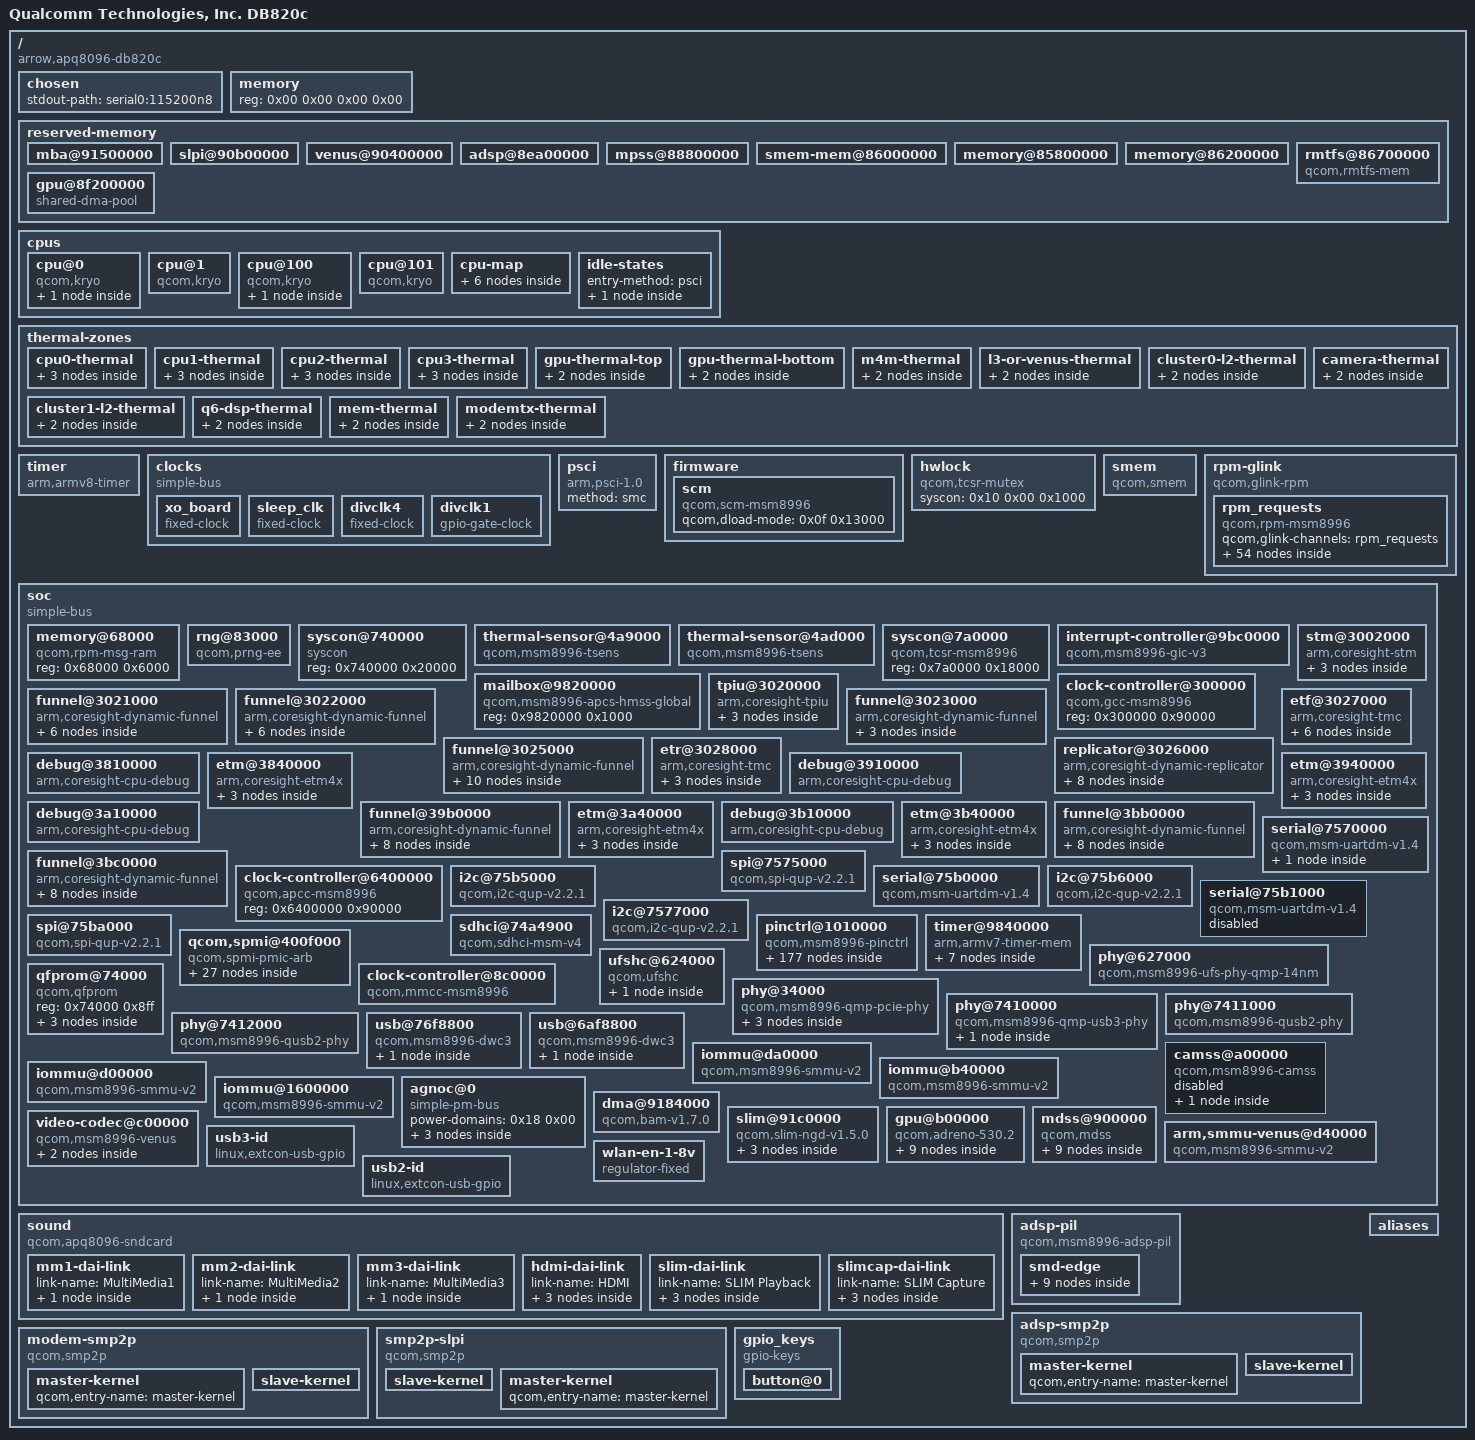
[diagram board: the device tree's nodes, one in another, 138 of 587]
/dts-v1/;

/ {
	interrupt-parent = <0x01>;
	#address-cells = <0x02>;
	#size-cells = <0x02>;
	model = "Qualcomm Technologies, Inc. DB820c";
	compatible = "arrow,apq8096-db820c\0qcom,apq8096-sbc\0qcom,apq8096";

	chosen {
		stdout-path = "serial0:115200n8";
	};

	memory {
		device_type = "memory";
		reg = <0x00 0x00 0x00 0x00>;
	};

	reserved-memory {
		#address-cells = <0x02>;
		#size-cells = <0x02>;
		ranges;

		mba@91500000 {
			reg = <0x00 0x91500000 0x00 0x200000>;
			no-map;
			phandle = <0x9d>;
		};

		slpi@90b00000 {
			reg = <0x00 0x90b00000 0x00 0xa00000>;
			no-map;
			phandle = <0x9e>;
		};

		venus@90400000 {
			reg = <0x00 0x90400000 0x00 0x700000>;
			no-map;
			phandle = <0x8f>;
		};

		adsp@8ea00000 {
			reg = <0x00 0x8ea00000 0x00 0x1a00000>;
			no-map;
			phandle = <0x99>;
		};

		mpss@88800000 {
			reg = <0x00 0x88800000 0x00 0x6200000>;
			no-map;
			phandle = <0x9f>;
		};

		smem-mem@86000000 {
			reg = <0x00 0x86000000 0x00 0x200000>;
			no-map;
			phandle = <0x11>;
		};

		memory@85800000 {
			reg = <0x00 0x85800000 0x00 0x800000>;
			no-map;
		};

		memory@86200000 {
			reg = <0x00 0x86200000 0x00 0x2600000>;
			no-map;
		};

		rmtfs@86700000 {
			compatible = "qcom,rmtfs-mem";
			size = <0x00 0x200000>;
			alloc-ranges = <0x00 0xa0000000 0x00 0x2000000>;
			no-map;
			qcom,client-id = <0x01>;
			qcom,vmid = <0x0f>;
		};

		gpu@8f200000 {
			compatible = "shared-dma-pool";
			reg = <0x00 0x90b00000 0x00 0xa00000>;
			no-map;
			phandle = <0x84>;
		};
	};

	cpus {
		#address-cells = <0x02>;
		#size-cells = <0x00>;

		cpu@0 {
			device_type = "cpu";
			compatible = "qcom,kryo";
			reg = <0x00 0x00>;
			enable-method = "psci";
			cpu-idle-states = <0x02>;
			capacity-dmips-mhz = <0x400>;
			next-level-cache = <0x03>;
			phandle = <0x05>;

			l2-cache {
				compatible = "cache";
				cache-level = <0x02>;
				phandle = <0x03>;
			};
		};

		cpu@1 {
			device_type = "cpu";
			compatible = "qcom,kryo";
			reg = <0x00 0x01>;
			enable-method = "psci";
			cpu-idle-states = <0x02>;
			capacity-dmips-mhz = <0x400>;
			next-level-cache = <0x03>;
			phandle = <0x06>;
		};

		cpu@100 {
			device_type = "cpu";
			compatible = "qcom,kryo";
			reg = <0x00 0x100>;
			enable-method = "psci";
			cpu-idle-states = <0x02>;
			capacity-dmips-mhz = <0x400>;
			next-level-cache = <0x04>;
			phandle = <0x07>;

			l2-cache {
				compatible = "cache";
				cache-level = <0x02>;
				phandle = <0x04>;
			};
		};

		cpu@101 {
			device_type = "cpu";
			compatible = "qcom,kryo";
			reg = <0x00 0x101>;
			enable-method = "psci";
			cpu-idle-states = <0x02>;
			capacity-dmips-mhz = <0x400>;
			next-level-cache = <0x04>;
			phandle = <0x08>;
		};

		cpu-map {

			cluster0 {

				core0 {
					cpu = <0x05>;
				};

				core1 {
					cpu = <0x06>;
				};
			};

			cluster1 {

				core0 {
					cpu = <0x07>;
				};

				core1 {
					cpu = <0x08>;
				};
			};
		};

		idle-states {
			entry-method = "psci";

			cpu-sleep-0 {
				compatible = "arm,idle-state";
				idle-state-name = "standalone-power-collapse";
				arm,psci-suspend-param = <0x04>;
				entry-latency-us = <0x82>;
				exit-latency-us = <0x50>;
				min-residency-us = <0x12c>;
				phandle = <0x02>;
			};
		};
	};

	thermal-zones {

		cpu0-thermal {
			polling-delay-passive = <0xfa>;
			polling-delay = <0x3e8>;
			thermal-sensors = <0x09 0x03>;

			trips {

				trip-point@0 {
					temperature = <0x124f8>;
					hysteresis = <0x7d0>;
					type = "passive";
					phandle = <0xa0>;
				};

				cpu_crit {
					temperature = <0x1adb0>;
					hysteresis = <0x7d0>;
					type = "critical";
					phandle = <0xa1>;
				};
			};
		};

		cpu1-thermal {
			polling-delay-passive = <0xfa>;
			polling-delay = <0x3e8>;
			thermal-sensors = <0x09 0x05>;

			trips {

				trip-point@0 {
					temperature = <0x124f8>;
					hysteresis = <0x7d0>;
					type = "passive";
					phandle = <0xa2>;
				};

				cpu_crit {
					temperature = <0x1adb0>;
					hysteresis = <0x7d0>;
					type = "critical";
					phandle = <0xa3>;
				};
			};
		};

		cpu2-thermal {
			polling-delay-passive = <0xfa>;
			polling-delay = <0x3e8>;
			thermal-sensors = <0x09 0x08>;

			trips {

				trip-point@0 {
					temperature = <0x124f8>;
					hysteresis = <0x7d0>;
					type = "passive";
					phandle = <0xa4>;
				};

				cpu_crit {
					temperature = <0x1adb0>;
					hysteresis = <0x7d0>;
					type = "critical";
					phandle = <0xa5>;
				};
			};
		};

		cpu3-thermal {
			polling-delay-passive = <0xfa>;
			polling-delay = <0x3e8>;
			thermal-sensors = <0x09 0x0a>;

			trips {

				trip-point@0 {
					temperature = <0x124f8>;
					hysteresis = <0x7d0>;
					type = "passive";
					phandle = <0xa6>;
				};

				cpu_crit {
					temperature = <0x1adb0>;
					hysteresis = <0x7d0>;
					type = "critical";
					phandle = <0xa7>;
				};
			};
		};

		gpu-thermal-top {
			polling-delay-passive = <0xfa>;
			polling-delay = <0x3e8>;
			thermal-sensors = <0x0a 0x06>;

			trips {

				trip-point@0 {
					temperature = <0x15f90>;
					hysteresis = <0x7d0>;
					type = "hot";
					phandle = <0xa8>;
				};
			};
		};

		gpu-thermal-bottom {
			polling-delay-passive = <0xfa>;
			polling-delay = <0x3e8>;
			thermal-sensors = <0x0a 0x07>;

			trips {

				trip-point@0 {
					temperature = <0x15f90>;
					hysteresis = <0x7d0>;
					type = "hot";
					phandle = <0xa9>;
				};
			};
		};

		m4m-thermal {
			polling-delay-passive = <0xfa>;
			polling-delay = <0x3e8>;
			thermal-sensors = <0x09 0x01>;

			trips {

				trip-point@0 {
					temperature = <0x15f90>;
					hysteresis = <0x7d0>;
					type = "hot";
					phandle = <0xaa>;
				};
			};
		};

		l3-or-venus-thermal {
			polling-delay-passive = <0xfa>;
			polling-delay = <0x3e8>;
			thermal-sensors = <0x09 0x02>;

			trips {

				trip-point@0 {
					temperature = <0x15f90>;
					hysteresis = <0x7d0>;
					type = "hot";
					phandle = <0xab>;
				};
			};
		};

		cluster0-l2-thermal {
			polling-delay-passive = <0xfa>;
			polling-delay = <0x3e8>;
			thermal-sensors = <0x09 0x07>;

			trips {

				trip-point@0 {
					temperature = <0x15f90>;
					hysteresis = <0x7d0>;
					type = "hot";
					phandle = <0xac>;
				};
			};
		};

		cluster1-l2-thermal {
			polling-delay-passive = <0xfa>;
			polling-delay = <0x3e8>;
			thermal-sensors = <0x09 0x0c>;

			trips {

				trip-point@0 {
					temperature = <0x15f90>;
					hysteresis = <0x7d0>;
					type = "hot";
					phandle = <0xad>;
				};
			};
		};

		camera-thermal {
			polling-delay-passive = <0xfa>;
			polling-delay = <0x3e8>;
			thermal-sensors = <0x0a 0x01>;

			trips {

				trip-point@0 {
					temperature = <0x15f90>;
					hysteresis = <0x7d0>;
					type = "hot";
					phandle = <0xae>;
				};
			};
		};

		q6-dsp-thermal {
			polling-delay-passive = <0xfa>;
			polling-delay = <0x3e8>;
			thermal-sensors = <0x0a 0x02>;

			trips {

				trip-point@0 {
					temperature = <0x15f90>;
					hysteresis = <0x7d0>;
					type = "hot";
					phandle = <0xaf>;
				};
			};
		};

		mem-thermal {
			polling-delay-passive = <0xfa>;
			polling-delay = <0x3e8>;
			thermal-sensors = <0x0a 0x03>;

			trips {

				trip-point@0 {
					temperature = <0x15f90>;
					hysteresis = <0x7d0>;
					type = "hot";
					phandle = <0xb0>;
				};
			};
		};

		modemtx-thermal {
			polling-delay-passive = <0xfa>;
			polling-delay = <0x3e8>;
			thermal-sensors = <0x0a 0x04>;

			trips {

				trip-point@0 {
					temperature = <0x15f90>;
					hysteresis = <0x7d0>;
					type = "hot";
					phandle = <0xb1>;
				};
			};
		};
	};

	timer {
		compatible = "arm,armv8-timer";
		interrupts = <0x01 0x0d 0x08 0x01 0x0e 0x08 0x01 0x0b 0x08 0x01 0x0a 0x08>;
	};

	clocks {
		compatible = "simple-bus";

		xo_board {
			compatible = "fixed-clock";
			#clock-cells = <0x00>;
			clock-frequency = <0x124f800>;
			clock-output-names = "xo_board";
			phandle = <0x48>;
		};

		sleep_clk {
			compatible = "fixed-clock";
			#clock-cells = <0x00>;
			clock-frequency = <0x7ffc>;
			clock-output-names = "sleep_clk";
			phandle = <0xb2>;
		};

		divclk4 {
			compatible = "fixed-clock";
			#clock-cells = <0x00>;
			clock-frequency = <0x8000>;
			clock-output-names = "divclk4";
			pinctrl-names = "default";
			pinctrl-0 = <0x0b>;
			phandle = <0x39>;
		};

		divclk1 {
			compatible = "gpio-gate-clock";
			pinctrl-0 = <0x0c>;
			pinctrl-names = "default";
			clocks = <0x0d 0x2e>;
			#clock-cells = <0x00>;
			enable-gpios = <0x0e 0x0f 0x00>;
			phandle = <0x80>;
		};
	};

	psci {
		compatible = "arm,psci-1.0";
		method = "smc";
	};

	firmware {

		scm {
			compatible = "qcom,scm-msm8996";
			qcom,dload-mode = <0x0f 0x13000>;
		};
	};

	hwlock {
		compatible = "qcom,tcsr-mutex";
		syscon = <0x10 0x00 0x1000>;
		#hwlock-cells = <0x01>;
		phandle = <0x12>;
	};

	smem {
		compatible = "qcom,smem";
		memory-region = <0x11>;
		hwlocks = <0x12 0x03>;
	};

	rpm-glink {
		compatible = "qcom,glink-rpm";
		interrupts = <0x00 0xa8 0x01>;
		qcom,rpm-msg-ram = <0x13>;
		mboxes = <0x14 0x00>;

		rpm_requests {
			compatible = "qcom,rpm-msm8996";
			qcom,glink-channels = "rpm_requests";

			qcom,rpmcc {
				compatible = "qcom,rpmcc-msm8996";
				#clock-cells = <0x01>;
				phandle = <0x0d>;
			};

			power-controller {
				compatible = "qcom,msm8996-rpmpd";
				#power-domain-cells = <0x01>;
				operating-points-v2 = <0x15>;
				phandle = <0xb3>;

				opp-table {
					compatible = "operating-points-v2";
					phandle = <0x15>;

					opp1 {
						opp-level = <0x01>;
						phandle = <0xb4>;
					};

					opp2 {
						opp-level = <0x02>;
						phandle = <0xb5>;
					};

					opp3 {
						opp-level = <0x03>;
						phandle = <0xb6>;
					};

					opp4 {
						opp-level = <0x04>;
						phandle = <0xb7>;
					};

					opp5 {
						opp-level = <0x05>;
						phandle = <0xb8>;
					};

					opp6 {
						opp-level = <0x06>;
						phandle = <0xb9>;
					};
				};
			};

			pm8994-regulators {
				compatible = "qcom,rpm-pm8994-regulators";
				vdd_l1-supply = <0x16>;
				vdd_l2_l26_l28-supply = <0x16>;
				vdd_l3_l11-supply = <0x16>;
				vdd_l4_l27_l31-supply = <0x16>;
				vdd_l5_l7-supply = <0x17>;
				vdd_l14_l15-supply = <0x17>;
				vdd_l20_l21-supply = <0x17>;
				vdd_l25-supply = <0x16>;

				s1 {
					phandle = <0xba>;
				};

				s2 {
					phandle = <0xbb>;
				};

				s3 {
					regulator-min-microvolt = <0x13d620>;
					regulator-max-microvolt = <0x13d620>;
					phandle = <0x16>;
				};

				s4 {
					regulator-min-microvolt = <0x1b7740>;
					regulator-max-microvolt = <0x1b7740>;
					regulator-always-on;
					phandle = <0x5d>;
				};

				s5 {
					regulator-min-microvolt = <0x20ce70>;
					regulator-max-microvolt = <0x20ce70>;
					phandle = <0x17>;
				};

				s6 {
					phandle = <0xbc>;
				};

				s7 {
					regulator-min-microvolt = <0xc3500>;
					regulator-max-microvolt = <0xc3500>;
					phandle = <0xbd>;
				};

				s8 {
					phandle = <0xbe>;
				};

				s9 {
					phandle = <0xbf>;
				};

				s10 {
					phandle = <0xc0>;
				};

				s11 {
					phandle = <0xc1>;
				};

				s12 {
					phandle = <0xc2>;
				};

				l1 {
					regulator-min-microvolt = <0xf4240>;
					regulator-max-microvolt = <0xf4240>;
					phandle = <0xc3>;
				};

				l2 {
					regulator-min-microvolt = <0x1312d0>;
					regulator-max-microvolt = <0x1312d0>;
					phandle = <0x67>;
				};

				l3 {
					regulator-min-microvolt = <0xcf850>;
					regulator-max-microvolt = <0xcf850>;
					phandle = <0xc4>;
				};

				l4 {
					regulator-min-microvolt = <0x12b128>;
					regulator-max-microvolt = <0x12b128>;
					phandle = <0xc5>;
				};

				l5 {
					phandle = <0xc6>;
				};

				l6 {
					regulator-min-microvolt = <0x124f80>;
					regulator-max-microvolt = <0x124f80>;
					phandle = <0xc7>;
				};

				l7 {
					phandle = <0xc8>;
				};

				l8 {
					regulator-min-microvolt = <0x1b7740>;
					regulator-max-microvolt = <0x1b7740>;
					phandle = <0xc9>;
				};

				l9 {
					regulator-min-microvolt = <0x1b7740>;
					regulator-max-microvolt = <0x1b7740>;
					phandle = <0xca>;
				};

				l10 {
					regulator-min-microvolt = <0x1b7740>;
					regulator-max-microvolt = <0x1b7740>;
					phandle = <0xcb>;
				};

				l11 {
					regulator-min-microvolt = <0x118c30>;
					regulator-max-microvolt = <0x118c30>;
					phandle = <0xcc>;
				};

				l12 {
					regulator-min-microvolt = <0x1b7740>;
					regulator-max-microvolt = <0x1b7740>;
					phandle = <0x58>;
				};

				l13 {
					regulator-min-microvolt = <0x1b7740>;
					regulator-max-microvolt = <0x2d0370>;
					phandle = <0x53>;
				};

				l14 {
					regulator-min-microvolt = <0x1b7740>;
					regulator-max-microvolt = <0x1b7740>;
					phandle = <0xcd>;
				};

				l15 {
					regulator-min-microvolt = <0x1b7740>;
					regulator-max-microvolt = <0x1b7740>;
					phandle = <0xce>;
				};

				l16 {
					regulator-min-microvolt = <0x2932e0>;
					regulator-max-microvolt = <0x2932e0>;
					phandle = <0xcf>;
				};

				l17 {
					regulator-min-microvolt = <0x2625a0>;
					regulator-max-microvolt = <0x2625a0>;
					phandle = <0xd0>;
				};

				l18 {
					regulator-min-microvolt = <0x2932e0>;
					regulator-max-microvolt = <0x2c4020>;
					phandle = <0xd1>;
				};

				l19 {
					regulator-min-microvolt = <0x2dc6c0>;
					regulator-max-microvolt = <0x2dc6c0>;
					phandle = <0xd2>;
				};

				l20 {
					regulator-min-microvolt = <0x2d0370>;
					regulator-max-microvolt = <0x2d0370>;
					regulator-allow-set-load;
					phandle = <0x5c>;
				};

				l21 {
					regulator-min-microvolt = <0x2d0370>;
					regulator-max-microvolt = <0x2d0370>;
					regulator-allow-set-load;
					regulator-system-load = <0x30d40>;
					phandle = <0x52>;
				};

				l22 {
					regulator-min-microvolt = <0x325aa0>;
					regulator-max-microvolt = <0x325aa0>;
					phandle = <0xd3>;
				};

				l23 {
					regulator-min-microvolt = <0x2ab980>;
					regulator-max-microvolt = <0x2ab980>;
					phandle = <0xd4>;
				};

				l24 {
					regulator-min-microvolt = <0x2eebb8>;
					regulator-max-microvolt = <0x2eebb8>;
					phandle = <0x5f>;
				};

				l25 {
					regulator-min-microvolt = <0x124f80>;
					regulator-max-microvolt = <0x124f80>;
					regulator-allow-set-load;
					phandle = <0x59>;
				};

				l26 {
					phandle = <0xd5>;
				};

				l27 {
					regulator-min-microvolt = <0xf4240>;
					regulator-max-microvolt = <0xf4240>;
					phandle = <0xd6>;
				};

				l28 {
					regulator-min-microvolt = <0xe1d48>;
					regulator-max-microvolt = <0xe1d48>;
					regulator-allow-set-load;
					phandle = <0x57>;
				};

				l29 {
					regulator-min-microvolt = <0x2ab980>;
					regulator-max-microvolt = <0x2ab980>;
					phandle = <0xd7>;
				};

				l30 {
					regulator-min-microvolt = <0x1b7740>;
					regulator-max-microvolt = <0x1b7740>;
					phandle = <0xd8>;
				};

				l31 {
					phandle = <0xd9>;
				};

				l32 {
					regulator-min-microvolt = <0x1b7740>;
					regulator-max-microvolt = <0x1b7740>;
					phandle = <0xda>;
				};
			};
		};
	};

	soc {
		#address-cells = <0x01>;
		#size-cells = <0x01>;
		ranges = <0x00 0x00 0x00 0xffffffff>;
		compatible = "simple-bus";
		phandle = <0xdb>;

		memory@68000 {
			compatible = "qcom,rpm-msg-ram";
			reg = <0x68000 0x6000>;
			phandle = <0x13>;
		};

		rng@83000 {
			compatible = "qcom,prng-ee";
			reg = <0x83000 0x1000>;
			clocks = <0x18 0x98>;
			clock-names = "core";
			phandle = <0xdc>;
		};

		syscon@740000 {
			compatible = "syscon";
			reg = <0x740000 0x20000>;
			phandle = <0x10>;
		};

		thermal-sensor@4a9000 {
			compatible = "qcom,msm8996-tsens";
			reg = <0x4a9000 0x1000 0x4a8000 0x1000>;
			#qcom,sensors = <0x0d>;
			#thermal-sensor-cells = <0x01>;
			phandle = <0x09>;
		};

		thermal-sensor@4ad000 {
			compatible = "qcom,msm8996-tsens";
			reg = <0x4ad000 0x1000 0x4ac000 0x1000>;
			#qcom,sensors = <0x08>;
			#thermal-sensor-cells = <0x01>;
			phandle = <0x0a>;
		};

		syscon@7a0000 {
			compatible = "qcom,tcsr-msm8996\0syscon";
			reg = <0x7a0000 0x18000>;
			phandle = <0x0f>;
		};

		interrupt-controller@9bc0000 {
			compatible = "qcom,msm8996-gic-v3\0arm,gic-v3";
			#interrupt-cells = <0x03>;
			interrupt-controller;
			#redistributor-regions = <0x01>;
			redistributor-stride = <0x00 0x40000>;
			reg = <0x9bc0000 0x10000 0x9c00000 0x100000>;
			interrupts = <0x01 0x09 0x04>;
			phandle = <0x01>;
		};

		mailbox@9820000 {
			compatible = "qcom,msm8996-apcs-hmss-global";
			reg = <0x9820000 0x1000>;
			#mbox-cells = <0x01>;
			phandle = <0x14>;
		};

		clock-controller@300000 {
			compatible = "qcom,gcc-msm8996";
			#clock-cells = <0x01>;
			#reset-cells = <0x01>;
			#power-domain-cells = <0x01>;
			reg = <0x300000 0x90000>;
			phandle = <0x18>;
		};

		stm@3002000 {
			compatible = "arm,coresight-stm\0arm,primecell";
			reg = <0x3002000 0x1000 0x8280000 0x180000>;
			reg-names = "stm-base\0stm-stimulus-base";
			clocks = <0x0d 0x08 0x0d 0x09>;
			clock-names = "apb_pclk\0atclk";

			out-ports {

				port {

					endpoint {
						remote-endpoint = <0x19>;
						phandle = <0x1b>;
					};
				};
			};
		};

		tpiu@3020000 {
			compatible = "arm,coresight-tpiu\0arm,primecell";
			reg = <0x3020000 0x1000>;
			clocks = <0x0d 0x08 0x0d 0x09>;
			clock-names = "apb_pclk\0atclk";

			in-ports {

				port {

					endpoint {
						remote-endpoint = <0x1a>;
						phandle = <0x26>;
					};
				};
			};
		};

		funnel@3021000 {
			compatible = "arm,coresight-dynamic-funnel\0arm,primecell";
			reg = <0x3021000 0x1000>;
			clocks = <0x0d 0x08 0x0d 0x09>;
			clock-names = "apb_pclk\0atclk";

			in-ports {
				#address-cells = <0x01>;
				#size-cells = <0x00>;

				port@7 {
					reg = <0x07>;

					endpoint {
						remote-endpoint = <0x1b>;
						phandle = <0x19>;
					};
				};
			};

			out-ports {

				port {

					endpoint {
						remote-endpoint = <0x1c>;
						phandle = <0x20>;
					};
				};
			};
		};

		funnel@3022000 {
			compatible = "arm,coresight-dynamic-funnel\0arm,primecell";
			reg = <0x3022000 0x1000>;
			clocks = <0x0d 0x08 0x0d 0x09>;
			clock-names = "apb_pclk\0atclk";

			in-ports {
				#address-cells = <0x01>;
				#size-cells = <0x00>;

				port@6 {
					reg = <0x06>;

					endpoint {
						remote-endpoint = <0x1d>;
						phandle = <0x36>;
					};
				};
			};

			out-ports {

				port {

					endpoint {
						remote-endpoint = <0x1e>;
						phandle = <0x21>;
					};
				};
			};
		};

		funnel@3023000 {
			compatible = "arm,coresight-dynamic-funnel\0arm,primecell";
			reg = <0x3023000 0x1000>;
			clocks = <0x0d 0x08 0x0d 0x09>;
			clock-names = "apb_pclk\0atclk";

			out-ports {

				port {

					endpoint {
						remote-endpoint = <0x1f>;
						phandle = <0x22>;
					};
				};
			};
		};

		funnel@3025000 {
			compatible = "arm,coresight-dynamic-funnel\0arm,primecell";
			reg = <0x3025000 0x1000>;
			clocks = <0x0d 0x08 0x0d 0x09>;
			clock-names = "apb_pclk\0atclk";

			in-ports {
				#address-cells = <0x01>;
				#size-cells = <0x00>;

				port@0 {
					reg = <0x00>;

					endpoint {
						remote-endpoint = <0x20>;
						phandle = <0x1c>;
					};
				};

				port@1 {
					reg = <0x01>;

					endpoint {
						remote-endpoint = <0x21>;
						phandle = <0x1e>;
					};
				};

				port@2 {
					reg = <0x02>;

					endpoint {
						remote-endpoint = <0x22>;
						phandle = <0x1f>;
					};
				};
			};

			out-ports {

				port {

					endpoint {
						remote-endpoint = <0x23>;
						phandle = <0x27>;
					};
				};
			};
		};

		replicator@3026000 {
			compatible = "arm,coresight-dynamic-replicator\0arm,primecell";
			reg = <0x3026000 0x1000>;
			clocks = <0x0d 0x08 0x0d 0x09>;
			clock-names = "apb_pclk\0atclk";

			in-ports {

				port {

					endpoint {
						remote-endpoint = <0x24>;
						phandle = <0x28>;
					};
				};
			};

			out-ports {
				#address-cells = <0x01>;
				#size-cells = <0x00>;

				port@0 {
					reg = <0x00>;

					endpoint {
						remote-endpoint = <0x25>;
						phandle = <0x29>;
					};
				};

				port@1 {
					reg = <0x01>;

					endpoint {
						remote-endpoint = <0x26>;
						phandle = <0x1a>;
					};
				};
			};
		};

		etf@3027000 {
			compatible = "arm,coresight-tmc\0arm,primecell";
			reg = <0x3027000 0x1000>;
			clocks = <0x0d 0x08 0x0d 0x09>;
			clock-names = "apb_pclk\0atclk";

			in-ports {

				port {

					endpoint {
						remote-endpoint = <0x27>;
						phandle = <0x23>;
					};
				};
			};

			out-ports {

				port {

					endpoint {
						remote-endpoint = <0x28>;
						phandle = <0x24>;
					};
				};
			};
		};

		etr@3028000 {
			compatible = "arm,coresight-tmc\0arm,primecell";
			reg = <0x3028000 0x1000>;
			clocks = <0x0d 0x08 0x0d 0x09>;
			clock-names = "apb_pclk\0atclk";
			arm,scatter-gather;

			in-ports {

				port {

					endpoint {
						remote-endpoint = <0x29>;
						phandle = <0x25>;
					};
				};
			};
		};

		debug@3810000 {
			compatible = "arm,coresight-cpu-debug\0arm,primecell";
			reg = <0x3810000 0x1000>;
			clocks = <0x0d 0x08>;
			clock-names = "apb_pclk";
			cpu = <0x05>;
		};

		etm@3840000 {
			compatible = "arm,coresight-etm4x\0arm,primecell";
			reg = <0x3840000 0x1000>;
			clocks = <0x0d 0x08 0x0d 0x09>;
			clock-names = "apb_pclk\0atclk";
			cpu = <0x05>;

			out-ports {

				port {

					endpoint {
						remote-endpoint = <0x2a>;
						phandle = <0x2c>;
					};
				};
			};
		};

		debug@3910000 {
			compatible = "arm,coresight-cpu-debug\0arm,primecell";
			reg = <0x3910000 0x1000>;
			clocks = <0x0d 0x08>;
			clock-names = "apb_pclk";
			cpu = <0x06>;
		};

		etm@3940000 {
			compatible = "arm,coresight-etm4x\0arm,primecell";
			reg = <0x3940000 0x1000>;
			clocks = <0x0d 0x08 0x0d 0x09>;
			clock-names = "apb_pclk\0atclk";
			cpu = <0x06>;

			out-ports {

				port {

					endpoint {
						remote-endpoint = <0x2b>;
						phandle = <0x2d>;
					};
				};
			};
		};

		funnel@39b0000 {
			compatible = "arm,coresight-dynamic-funnel\0arm,primecell";
			reg = <0x39b0000 0x1000>;
			clocks = <0x0d 0x08 0x0d 0x09>;
			clock-names = "apb_pclk\0atclk";

			in-ports {
				#address-cells = <0x01>;
				#size-cells = <0x00>;

				port@0 {
					reg = <0x00>;

					endpoint {
						remote-endpoint = <0x2c>;
						phandle = <0x2a>;
					};
				};

				port@1 {
					reg = <0x01>;

					endpoint {
						remote-endpoint = <0x2d>;
						phandle = <0x2b>;
					};
				};
			};

			out-ports {

				port {

					endpoint {
						remote-endpoint = <0x2e>;
						phandle = <0x34>;
					};
				};
			};
		};

		debug@3a10000 {
			compatible = "arm,coresight-cpu-debug\0arm,primecell";
			reg = <0x3a10000 0x1000>;
			clocks = <0x0d 0x08>;
			clock-names = "apb_pclk";
			cpu = <0x07>;
		};

		etm@3a40000 {
			compatible = "arm,coresight-etm4x\0arm,primecell";
			reg = <0x3a40000 0x1000>;
			clocks = <0x0d 0x08 0x0d 0x09>;
			clock-names = "apb_pclk\0atclk";
			cpu = <0x07>;

			out-ports {

				port {

					endpoint {
						remote-endpoint = <0x2f>;
						phandle = <0x31>;
					};
				};
			};
		};

		debug@3b10000 {
			compatible = "arm,coresight-cpu-debug\0arm,primecell";
			reg = <0x3b10000 0x1000>;
			clocks = <0x0d 0x08>;
			clock-names = "apb_pclk";
			cpu = <0x08>;
		};

		etm@3b40000 {
			compatible = "arm,coresight-etm4x\0arm,primecell";
			reg = <0x3b40000 0x1000>;
			clocks = <0x0d 0x08 0x0d 0x09>;
			clock-names = "apb_pclk\0atclk";
			cpu = <0x08>;

			out-ports {

				port {

					endpoint {
						remote-endpoint = <0x30>;
						phandle = <0x32>;
					};
				};
			};
		};

		funnel@3bb0000 {
			compatible = "arm,coresight-dynamic-funnel\0arm,primecell";
			reg = <0x3bb0000 0x1000>;
			clocks = <0x0d 0x08 0x0d 0x09>;
			clock-names = "apb_pclk\0atclk";

			in-ports {
				#address-cells = <0x01>;
				#size-cells = <0x00>;

				port@0 {
					reg = <0x00>;

					endpoint {
						remote-endpoint = <0x31>;
						phandle = <0x2f>;
					};
				};

				port@1 {
					reg = <0x01>;

					endpoint {
						remote-endpoint = <0x32>;
						phandle = <0x30>;
					};
				};
			};

			out-ports {

				port {

					endpoint {
						remote-endpoint = <0x33>;
						phandle = <0x35>;
					};
				};
			};
		};

		funnel@3bc0000 {
			compatible = "arm,coresight-dynamic-funnel\0arm,primecell";
			reg = <0x3bc0000 0x1000>;
			clocks = <0x0d 0x08 0x0d 0x09>;
			clock-names = "apb_pclk\0atclk";

			in-ports {
				#address-cells = <0x01>;
				#size-cells = <0x00>;

				port@0 {
					reg = <0x00>;

					endpoint {
						remote-endpoint = <0x34>;
						phandle = <0x2e>;
					};
				};

				port@1 {
					reg = <0x01>;

					endpoint {
						remote-endpoint = <0x35>;
						phandle = <0x33>;
					};
				};
			};

			out-ports {

				port {

					endpoint {
						remote-endpoint = <0x36>;
						phandle = <0x1d>;
					};
				};
			};
		};

		clock-controller@6400000 {
			compatible = "qcom,apcc-msm8996";
			reg = <0x6400000 0x90000>;
			#clock-cells = <0x01>;
			phandle = <0xdd>;
		};

		serial@7570000 {
			compatible = "qcom,msm-uartdm-v1.4\0qcom,msm-uartdm";
			reg = <0x7570000 0x1000>;
			interrupts = <0x00 0x6c 0x04>;
			clocks = <0x18 0x74 0x18 0x6d>;
			clock-names = "core\0iface";
			status = "okay";
			label = "BT-UART";
			pinctrl-names = "default\0sleep";
			pinctrl-0 = <0x37>;
			pinctrl-1 = <0x38>;
			phandle = <0xde>;

			bluetooth {
				compatible = "qcom,qca6174-bt";
				enable-gpios = <0x0e 0x13 0x00>;
				clocks = <0x39>;
			};
		};

		spi@7575000 {
			compatible = "qcom,spi-qup-v2.2.1";
			reg = <0x7575000 0x600>;
			interrupts = <0x00 0x5f 0x04>;
			clocks = <0x18 0x6f 0x18 0x6d>;
			clock-names = "core\0iface";
			pinctrl-names = "default\0sleep";
			pinctrl-0 = <0x3a>;
			pinctrl-1 = <0x3b>;
			#address-cells = <0x01>;
			#size-cells = <0x00>;
			status = "okay";
			label = "LS-SPI0";
			phandle = <0xdf>;
		};

		i2c@75b5000 {
			compatible = "qcom,i2c-qup-v2.2.1";
			reg = <0x75b5000 0x1000>;
			interrupts = <0x00 0x65 0x04>;
			clocks = <0x18 0x81 0x18 0x84>;
			clock-names = "iface\0core";
			pinctrl-names = "default\0sleep";
			pinctrl-0 = <0x3c>;
			pinctrl-1 = <0x3d>;
			#address-cells = <0x01>;
			#size-cells = <0x00>;
			status = "okay";
			label = "HS-I2C2";
			phandle = <0xe0>;
		};

		serial@75b0000 {
			compatible = "qcom,msm-uartdm-v1.4\0qcom,msm-uartdm";
			reg = <0x75b0000 0x1000>;
			interrupts = <0x00 0x72 0x04>;
			clocks = <0x18 0x88 0x18 0x81>;
			clock-names = "core\0iface";
			status = "okay";
			label = "LS-UART1";
			pinctrl-names = "default\0sleep";
			pinctrl-0 = <0x3e>;
			pinctrl-1 = <0x3f>;
			phandle = <0xe1>;
		};

		i2c@75b6000 {
			compatible = "qcom,i2c-qup-v2.2.1";
			reg = <0x75b6000 0x1000>;
			interrupts = <0x00 0x66 0x04>;
			clocks = <0x18 0x81 0x18 0x87>;
			clock-names = "iface\0core";
			pinctrl-names = "default\0sleep";
			pinctrl-0 = <0x40>;
			pinctrl-1 = <0x41>;
			#address-cells = <0x01>;
			#size-cells = <0x00>;
			status = "okay";
			label = "LS-I2C1";
			phandle = <0xe2>;
		};

		serial@75b1000 {
			compatible = "qcom,msm-uartdm-v1.4\0qcom,msm-uartdm";
			reg = <0x75b1000 0x1000>;
			interrupts = <0x00 0x73 0x04>;
			clocks = <0x18 0x8b 0x18 0x81>;
			clock-names = "core\0iface";
			status = "disabled";
			label = "LS-UART0";
			pinctrl-names = "default\0sleep";
			pinctrl-0 = <0x42>;
			pinctrl-1 = <0x43>;
			phandle = <0xe3>;
		};

		i2c@7577000 {
			compatible = "qcom,i2c-qup-v2.2.1";
			reg = <0x7577000 0x1000>;
			interrupts = <0x00 0x61 0x04>;
			clocks = <0x18 0x6d 0x18 0x76>;
			clock-names = "iface\0core";
			pinctrl-names = "default\0sleep";
			pinctrl-0 = <0x44>;
			pinctrl-1 = <0x45>;
			#address-cells = <0x01>;
			#size-cells = <0x00>;
			status = "okay";
			label = "LS-I2C0";
			phandle = <0xe4>;
		};

		spi@75ba000 {
			compatible = "qcom,spi-qup-v2.2.1";
			reg = <0x75ba000 0x600>;
			interrupts = <0x00 0x6a 0x04>;
			clocks = <0x18 0x92 0x18 0x81>;
			clock-names = "core\0iface";
			pinctrl-names = "default\0sleep";
			pinctrl-0 = <0x46>;
			pinctrl-1 = <0x47>;
			#address-cells = <0x01>;
			#size-cells = <0x00>;
			status = "okay";
			label = "HS-SPI1";
			phandle = <0xe5>;
		};

		sdhci@74a4900 {
			status = "okay";
			compatible = "qcom,sdhci-msm-v4";
			reg = <0x74a4900 0x314 0x74a4000 0x800>;
			reg-names = "hc_mem\0core_mem";
			interrupts = <0x00 0x7d 0x04 0x00 0xdd 0x04>;
			interrupt-names = "hc_irq\0pwr_irq";
			clock-names = "iface\0core\0xo";
			clocks = <0x18 0x68 0x18 0x67 0x48>;
			bus-width = <0x04>;
			pinctrl-names = "default\0sleep";
			pinctrl-0 = <0x49 0x4a 0x4b 0x4c>;
			pinctrl-1 = <0x4d 0x4e 0x4f 0x50>;
			cd-gpios = <0x51 0x26 0x01>;
			vmmc-supply = <0x52>;
			vqmmc-supply = <0x53>;
			phandle = <0xe6>;
		};

		pinctrl@1010000 {
			compatible = "qcom,msm8996-pinctrl";
			reg = <0x1010000 0x300000>;
			interrupts = <0x00 0xd0 0x04>;
			gpio-controller;
			#gpio-cells = <0x02>;
			interrupt-controller;
			#interrupt-cells = <0x02>;
			gpio-line-names = "[SPI0_DOUT]\0[SPI0_DIN]\0[SPI0_CS]\0[SPI0_SCLK]\0[UART1_TxD]\0[UART1_RxD]\0[I2C1_SDA]\0[I2C1_SCL]\0GPIO-H\0TP93\0GPIO-G\0[MDP_VSYNC_S]\0NC\0[CSI0_MCLK]\0[CAM_MCLK1]\0[CSI1_MCLK]\0TP99\0[I2C2_SDA]\0[I2C2_SCL]\0[CCI_I2C_SDA1]\0[CCI_I2C_SCL1]\0FLASH_STROBE_EN\0FLASH_STROBE_TRIG\0GPIO-K\0GPIO-D\0GPIO-I\0GPIO-J\0BLSP6_I2C_SDA\0BLSP6_I2C_SCL\0GPIO-B\0GPIO30\0HDMI_CEC\0HDMI_DDC_CLOCK\0HDMI_DDC_DATA\0HDMI_HOT_PLUG_DETECT\0PCIE0_RST_N\0PCIE0_CLKREQ_N\0PCIE0_WAKE\0SD_CARD_DET_N\0TSIF1_SYNC\0W_DISABLE_N\0[BLSP9_UART_TX]\0[BLSP9_UART_RX]\0[BLSP2_UART_CTS_N]\0[BLSP2_UART_RFR_N]\0[BLSP3_UART_TX]\0[BLSP3_UART_RX]\0[I2C0_SDA]\0[I2C0_SCL]\0[UART0_TxD]\0[UART0_RxD]\0[UART0_CTS]\0[UART0_RTS]\0[CODEC_INT1_N]\0[CODEC_INT2_N]\0[BLSP7_I2C_SDA]\0[BLSP7_I2C_SCL]\0MI2S_MCLK\0[PCM_CLK]\0[PCM_FS]\0[PCM_DO]\0[PCM_DI]\0GPIO-E\0TP87\0[CODEC_RST_N]\0[PCM1_CLK]\0[PCM1_SYNC]\0[PCM1_DIN]\0[PCM1_DOUT]\0AUDIO_REF_CLK\0SLIMBUS_CLK\0SLIMBUS_DATA0\0SLIMBUS_DATA1\0NC\0NC\0NC\0NC\0TP94\0NC\0TP95\0GPIO-A\0TP88\0TP89\0TP90\0TP91\0[SD_DAT0]\0[SD_CMD]\0[SD_DAT3]\0[SD_SCLK]\0TSIF1_CLK\0TSIF1_EN\0TSIF1_DATA\0NC\0TSIF2_CLK\0TSIF2_EN\0TSIF2_DATA\0TSIF2_SYNC\0NC\0CAM1_STANDBY_N\0NC\0NC\0[LCD1_RESET_N]\0BOOT_CONFIG1\0USB_HUB_RESET\0CAM1_RST_N\0NC\0NC\0NC\0NC\0NC\0NC\0NC\0NC\0PMI8994_BUA\0PCIE2_RST_N\0PCIE2_CLKREQ_N\0PCIE2_WAKE\0SSC_IRQ_0\0SSC_IRQ_1\0SSC_IRQ_2\0NC\0GPIO121\0NC\0SSC_IRQ_6\0SSC_IRQ_7\0GPIO-C\0BOOT_CONFIG5\0NC\0NC\0BOOT_CONFIG7\0PCIE1_RST_N\0PCIE1_CLKREQ_N\0PCIE1_WAKE\0GPIO-L\0NC\0NC\0BOOT_CONFIG8\0NC\0NC\0GPS_SSBI2\0GPS_SSBI1\0NC\0NC\0NC\0BOOT_CONFIG6\0NC\0NC\0NC\0NC\0NC";
			phandle = <0x51>;

			wcd9xxx_intr {

				wcd_intr_default {
					phandle = <0x7e>;

					mux {
						pins = "gpio54";
						function = "gpio";
					};

					config {
						pins = "gpio54";
						drive-strength = <0x02>;
						bias-pull-down;
						input-enable;
					};
				};
			};

			cdc_reset_ctrl {

				cdc_reset_sleep {
					phandle = <0xe7>;

					mux {
						pins = "gpio64";
						function = "gpio";
					};

					config {
						pins = "gpio64";
						drive-strength = <0x10>;
						bias-disable;
						output-low;
					};
				};

				cdc_reset_active {
					phandle = <0x7d>;

					mux {
						pins = "gpio64";
						function = "gpio";
					};

					config {
						pins = "gpio64";
						drive-strength = <0x10>;
						bias-pull-down;
						output-high;
					};
				};
			};

			blsp1_spi0_default {
				phandle = <0x3a>;

				pinmux {
					function = "blsp_spi1";
					pins = "gpio0\0gpio1\0gpio3";
				};

				pinmux_cs {
					function = "gpio";
					pins = "gpio2";
				};

				pinconf {
					pins = "gpio0\0gpio1\0gpio3";
					drive-strength = <0x0c>;
					bias-disable;
				};

				pinconf_cs {
					pins = "gpio2";
					drive-strength = <0x10>;
					bias-disable;
					output-high;
				};
			};

			blsp1_spi0_sleep {
				phandle = <0x3b>;

				pinmux {
					function = "gpio";
					pins = "gpio0\0gpio1\0gpio2\0gpio3";
				};

				pinconf {
					pins = "gpio0\0gpio1\0gpio2\0gpio3";
					drive-strength = <0x02>;
					bias-pull-down;
				};
			};

			blsp1_i2c2_default {
				phandle = <0x44>;

				pinmux {
					function = "blsp_i2c3";
					pins = "gpio47\0gpio48";
				};

				pinconf {
					pins = "gpio47\0gpio48";
					drive-strength = <0x10>;
					bias-disable = <0x00>;
				};
			};

			blsp1_i2c2_sleep {
				phandle = <0x45>;

				pinmux {
					function = "gpio";
					pins = "gpio47\0gpio48";
				};

				pinconf {
					pins = "gpio47\0gpio48";
					drive-strength = <0x02>;
					bias-disable = <0x00>;
				};
			};

			blsp2_i2c0 {
				phandle = <0x3c>;

				pinmux {
					function = "blsp_i2c7";
					pins = "gpio55\0gpio56";
				};

				pinconf {
					pins = "gpio55\0gpio56";
					drive-strength = <0x10>;
					bias-disable;
				};
			};

			blsp2_i2c0_sleep {
				phandle = <0x3d>;

				pinmux {
					function = "gpio";
					pins = "gpio55\0gpio56";
				};

				pinconf {
					pins = "gpio55\0gpio56";
					drive-strength = <0x02>;
					bias-disable;
				};
			};

			blsp2_uart1_2pins {
				phandle = <0x3e>;

				pinmux {
					function = "blsp_uart8";
					pins = "gpio4\0gpio5";
				};

				pinconf {
					pins = "gpio4\0gpio5";
					drive-strength = <0x10>;
					bias-disable;
				};
			};

			blsp2_uart1_2pins_sleep {
				phandle = <0x3f>;

				pinmux {
					function = "gpio";
					pins = "gpio4\0gpio5";
				};

				pinconf {
					pins = "gpio4\0gpio5";
					drive-strength = <0x02>;
					bias-disable;
				};
			};

			blsp2_uart1_4pins {
				phandle = <0xe8>;

				pinmux {
					function = "blsp_uart8";
					pins = "gpio4\0gpio5\0gpio6\0gpio7";
				};

				pinconf {
					pins = "gpio4\0gpio5\0gpio6\0gpio7";
					drive-strength = <0x10>;
					bias-disable;
				};
			};

			blsp2_uart1_4pins_sleep {
				phandle = <0xe9>;

				pinmux {
					function = "gpio";
					pins = "gpio4\0gpio5\0gpio6\0gpio7";
				};

				pinconf {
					pins = "gpio4\0gpio5\0gpio6\0gpio7";
					drive-strength = <0x02>;
					bias-disable;
				};
			};

			blsp2_i2c1 {
				phandle = <0x40>;

				pinmux {
					function = "blsp_i2c8";
					pins = "gpio6\0gpio7";
				};

				pinconf {
					pins = "gpio6\0gpio7";
					drive-strength = <0x10>;
					bias-disable;
				};
			};

			blsp2_i2c1_sleep {
				phandle = <0x41>;

				pinmux {
					function = "gpio";
					pins = "gpio6\0gpio7";
				};

				pinconf {
					pins = "gpio6\0gpio7";
					drive-strength = <0x02>;
					bias-disable;
				};
			};

			blsp2_uart2_2pins {
				phandle = <0xea>;

				pinmux {
					function = "blsp_uart9";
					pins = "gpio49\0gpio50";
				};

				pinconf {
					pins = "gpio49\0gpio50";
					drive-strength = <0x10>;
					bias-disable;
				};
			};

			blsp2_uart2_2pins_sleep {
				phandle = <0xeb>;

				pinmux {
					function = "gpio";
					pins = "gpio49\0gpio50";
				};

				pinconf {
					pins = "gpio49\0gpio50";
					drive-strength = <0x02>;
					bias-disable;
				};
			};

			blsp2_uart2_4pins {
				phandle = <0x42>;

				pinmux {
					function = "blsp_uart9";
					pins = "gpio49\0gpio50\0gpio51\0gpio52";
				};

				pinconf {
					pins = "gpio49\0gpio50\0gpio51\0gpio52";
					drive-strength = <0x10>;
					bias-disable;
				};
			};

			blsp2_uart2_4pins_sleep {
				phandle = <0x43>;

				pinmux {
					function = "gpio";
					pins = "gpio49\0gpio50\0gpio51\0gpio52";
				};

				pinconf {
					pins = "gpio49\0gpio50\0gpio51\0gpio52";
					drive-strength = <0x02>;
					bias-disable;
				};
			};

			blsp2_spi5_default {
				phandle = <0x46>;

				pinmux {
					function = "blsp_spi12";
					pins = "gpio85\0gpio86\0gpio88";
				};

				pinmux_cs {
					function = "gpio";
					pins = "gpio87";
				};

				pinconf {
					pins = "gpio85\0gpio86\0gpio88";
					drive-strength = <0x0c>;
					bias-disable;
				};

				pinconf_cs {
					pins = "gpio87";
					drive-strength = <0x10>;
					bias-disable;
					output-high;
				};
			};

			blsp2_spi5_sleep {
				phandle = <0x47>;

				pinmux {
					function = "gpio";
					pins = "gpio85\0gpio86\0gpio87\0gpio88";
				};

				pinconf {
					pins = "gpio85\0gpio86\0gpio87\0gpio88";
					drive-strength = <0x02>;
					bias-pull-down;
				};
			};

			sdc2_clk_on {
				phandle = <0x49>;

				config {
					pins = "sdc2_clk";
					bias-disable;
					drive-strength = <0x10>;
				};
			};

			sdc2_clk_off {
				phandle = <0x4d>;

				config {
					pins = "sdc2_clk";
					bias-disable;
					drive-strength = <0x02>;
				};
			};

			sdc2_cmd_on {
				phandle = <0x4a>;

				config {
					pins = "sdc2_cmd";
					bias-pull-up;
					drive-strength = <0x0a>;
				};
			};

			sdc2_cmd_off {
				phandle = <0x4e>;

				config {
					pins = "sdc2_cmd";
					bias-pull-up;
					drive-strength = <0x02>;
				};
			};

			sdc2_data_on {
				phandle = <0x4b>;

				config {
					pins = "sdc2_data";
					bias-pull-up;
					drive-strength = <0x0a>;
				};
			};

			sdc2_data_off {
				phandle = <0x4f>;

				config {
					pins = "sdc2_data";
					bias-pull-up;
					drive-strength = <0x02>;
				};
			};

			pcie0_clkreq_default {
				phandle = <0x6a>;

				mux {
					pins = "gpio36";
					function = "pci_e0";
				};

				config {
					pins = "gpio36";
					drive-strength = <0x02>;
					bias-pull-up;
				};
			};

			pcie0_perst_default {
				phandle = <0x6b>;

				mux {
					pins = "gpio35";
					function = "gpio";
				};

				config {
					pins = "gpio35";
					drive-strength = <0x02>;
					bias-pull-down;
				};
			};

			pcie0_wake_default {
				phandle = <0x6c>;

				mux {
					pins = "gpio37";
					function = "gpio";
				};

				config {
					pins = "gpio37";
					drive-strength = <0x02>;
					bias-pull-up;
				};
			};

			pcie0_clkreq_sleep {
				phandle = <0x6d>;

				mux {
					pins = "gpio36";
					function = "gpio";
				};

				config {
					pins = "gpio36";
					drive-strength = <0x02>;
					bias-disable;
				};
			};

			pcie0_wake_sleep {
				phandle = <0x6e>;

				mux {
					pins = "gpio37";
					function = "gpio";
				};

				config {
					pins = "gpio37";
					drive-strength = <0x02>;
					bias-disable;
				};
			};

			pcie1_clkreq_default {
				phandle = <0x71>;

				mux {
					pins = "gpio131";
					function = "pci_e1";
				};

				config {
					pins = "gpio131";
					drive-strength = <0x02>;
					bias-pull-up;
				};
			};

			pcie1_perst_default {
				phandle = <0x72>;

				mux {
					pins = "gpio130";
					function = "gpio";
				};

				config {
					pins = "gpio130";
					drive-strength = <0x02>;
					bias-pull-down;
				};
			};

			pcie1_wake_default {
				phandle = <0x73>;

				mux {
					pins = "gpio132";
					function = "gpio";
				};

				config {
					pins = "gpio132";
					drive-strength = <0x02>;
					bias-pull-down;
				};
			};

			pcie1_clkreq_sleep {
				phandle = <0x74>;

				mux {
					pins = "gpio131";
					function = "gpio";
				};

				config {
					pins = "gpio131";
					drive-strength = <0x02>;
					bias-disable;
				};
			};

			pcie1_wake_sleep {
				phandle = <0x75>;

				mux {
					pins = "gpio132";
					function = "gpio";
				};

				config {
					pins = "gpio132";
					drive-strength = <0x02>;
					bias-disable;
				};
			};

			pcie2_clkreq_default {
				phandle = <0x77>;

				mux {
					pins = "gpio115";
					function = "pci_e2";
				};

				config {
					pins = "gpio115";
					drive-strength = <0x02>;
					bias-pull-up;
				};
			};

			pcie2_perst_default {
				phandle = <0x78>;

				mux {
					pins = "gpio114";
					function = "gpio";
				};

				config {
					pins = "gpio114";
					drive-strength = <0x02>;
					bias-pull-down;
				};
			};

			pcie2_wake_default {
				phandle = <0x79>;

				mux {
					pins = "gpio116";
					function = "gpio";
				};

				config {
					pins = "gpio116";
					drive-strength = <0x02>;
					bias-pull-down;
				};
			};

			pcie2_clkreq_sleep {
				phandle = <0x7a>;

				mux {
					pins = "gpio115";
					function = "gpio";
				};

				config {
					pins = "gpio115";
					drive-strength = <0x02>;
					bias-disable;
				};
			};

			pcie2_wake_sleep {
				phandle = <0x7b>;

				mux {
					pins = "gpio116";
					function = "gpio";
				};

				config {
					pins = "gpio116";
					drive-strength = <0x02>;
					bias-disable;
				};
			};

			cci0_default {
				phandle = <0xec>;

				pinmux {
					function = "cci_i2c";
					pins = "gpio17\0gpio18";
				};

				pinconf {
					pins = "gpio17\0gpio18";
					drive-strength = <0x10>;
					bias-disable;
				};
			};

			cci1_default {
				phandle = <0xed>;

				pinmux {
					function = "cci_i2c";
					pins = "gpio19\0gpio20";
				};

				pinconf {
					pins = "gpio19\0gpio20";
					drive-strength = <0x10>;
					bias-disable;
				};
			};

			camera_board_default {
				phandle = <0xee>;

				mux_pwdn {
					function = "gpio";
					pins = "gpio98";
				};

				config_pwdn {
					pins = "gpio98";
					drive-strength = <0x10>;
					bias-disable;
				};

				mux_rst {
					function = "gpio";
					pins = "gpio104";
				};

				config_rst {
					pins = "gpio104";
					drive-strength = <0x10>;
					bias-disable;
				};

				mux_mclk1 {
					function = "cam_mclk";
					pins = "gpio14";
				};

				config_mclk1 {
					pins = "gpio14";
					drive-strength = <0x10>;
					bias-disable;
				};
			};

			camera_front_default {
				phandle = <0xef>;

				mux_pwdn {
					function = "gpio";
					pins = "gpio133";
				};

				config_pwdn {
					pins = "gpio133";
					drive-strength = <0x10>;
					bias-disable;
				};

				mux_rst {
					function = "gpio";
					pins = "gpio23";
				};

				config_rst {
					pins = "gpio23";
					drive-strength = <0x10>;
					bias-disable;
				};

				mux_mclk2 {
					function = "cam_mclk";
					pins = "gpio15";
				};

				config_mclk2 {
					pins = "gpio15";
					drive-strength = <0x10>;
					bias-disable;
				};
			};

			camera_rear_default {
				phandle = <0xf0>;

				mux_pwdn {
					function = "gpio";
					pins = "gpio26";
				};

				config_pwdn {
					pins = "gpio26";
					drive-strength = <0x10>;
					bias-disable;
				};

				mux_rst {
					function = "gpio";
					pins = "gpio25";
				};

				config_rst {
					pins = "gpio25";
					drive-strength = <0x10>;
					bias-disable;
				};

				mux_mclk0 {
					function = "cam_mclk";
					pins = "gpio13";
				};

				config_mclk0 {
					pins = "gpio13";
					drive-strength = <0x10>;
					bias-disable;
				};
			};

			sdc2_cd_on {
				phandle = <0x4c>;

				mux {
					pins = "gpio38";
					function = "gpio";
				};

				config {
					pins = "gpio38";
					bias-pull-up;
					drive-strength = <0x10>;
				};
			};

			sdc2_cd_off {
				phandle = <0x50>;

				mux {
					pins = "gpio38";
					function = "gpio";
				};

				config {
					pins = "gpio38";
					bias-pull-up;
					drive-strength = <0x02>;
				};
			};

			blsp1_uart1_default {
				phandle = <0x37>;

				mux {
					pins = "gpio41\0gpio42\0gpio43\0gpio44";
					function = "blsp_uart2";
				};

				config {
					pins = "gpio41\0gpio42\0gpio43\0gpio44";
					drive-strength = <0x10>;
					bias-disable;
				};
			};

			blsp1_uart1_sleep {
				phandle = <0x38>;

				mux {
					pins = "gpio41\0gpio42\0gpio43\0gpio44";
					function = "gpio";
				};

				config {
					pins = "gpio41\0gpio42\0gpio43\0gpio44";
					drive-strength = <0x02>;
					bias-disable;
				};
			};

			hdmi_hpd_active {
				phandle = <0x89>;

				mux {
					pins = "gpio34";
					function = "hdmi_hot";
				};

				config {
					pins = "gpio34";
					bias-pull-down;
					drive-strength = <0x10>;
				};
			};

			hdmi_hpd_suspend {
				phandle = <0x8b>;

				mux {
					pins = "gpio34";
					function = "hdmi_hot";
				};

				config {
					pins = "gpio34";
					bias-pull-down;
					drive-strength = <0x02>;
				};
			};

			hdmi_ddc_active {
				phandle = <0x8a>;

				mux {
					pins = "gpio32\0gpio33";
					function = "hdmi_ddc";
				};

				config {
					pins = "gpio32\0gpio33";
					drive-strength = <0x02>;
					bias-pull-up;
				};
			};

			hdmi_ddc_suspend {
				phandle = <0x8c>;

				mux {
					pins = "gpio32\0gpio33";
					function = "hdmi_ddc";
				};

				config {
					pins = "gpio32\0gpio33";
					drive-strength = <0x02>;
					bias-pull-down;
				};
			};
		};

		timer@9840000 {
			#address-cells = <0x01>;
			#size-cells = <0x01>;
			ranges;
			compatible = "arm,armv7-timer-mem";
			reg = <0x9840000 0x1000>;
			clock-frequency = <0x124f800>;

			frame@9850000 {
				frame-number = <0x00>;
				interrupts = <0x00 0x1f 0x04 0x00 0x1e 0x04>;
				reg = <0x9850000 0x1000 0x9860000 0x1000>;
			};

			frame@9870000 {
				frame-number = <0x01>;
				interrupts = <0x00 0x20 0x04>;
				reg = <0x9870000 0x1000>;
				status = "disabled";
			};

			frame@9880000 {
				frame-number = <0x02>;
				interrupts = <0x00 0x21 0x04>;
				reg = <0x9880000 0x1000>;
				status = "disabled";
			};

			frame@9890000 {
				frame-number = <0x03>;
				interrupts = <0x00 0x22 0x04>;
				reg = <0x9890000 0x1000>;
				status = "disabled";
			};

			frame@98a0000 {
				frame-number = <0x04>;
				interrupts = <0x00 0x23 0x04>;
				reg = <0x98a0000 0x1000>;
				status = "disabled";
			};

			frame@98b0000 {
				frame-number = <0x05>;
				interrupts = <0x00 0x24 0x04>;
				reg = <0x98b0000 0x1000>;
				status = "disabled";
			};

			frame@98c0000 {
				frame-number = <0x06>;
				interrupts = <0x00 0x25 0x04>;
				reg = <0x98c0000 0x1000>;
				status = "disabled";
			};
		};

		qcom,spmi@400f000 {
			compatible = "qcom,spmi-pmic-arb";
			reg = <0x400f000 0x1000 0x4400000 0x800000 0x4c00000 0x800000 0x5800000 0x200000 0x400a000 0x2100>;
			reg-names = "core\0chnls\0obsrvr\0intr\0cnfg";
			interrupt-names = "periph_irq";
			interrupts = <0x00 0x146 0x04>;
			qcom,ee = <0x00>;
			qcom,channel = <0x00>;
			#address-cells = <0x02>;
			#size-cells = <0x00>;
			interrupt-controller;
			#interrupt-cells = <0x04>;
			phandle = <0xf1>;

			pmic@0 {
				compatible = "qcom,pm8994\0qcom,spmi-pmic";
				reg = <0x00 0x00>;
				#address-cells = <0x01>;
				#size-cells = <0x00>;

				rtc@6000 {
					compatible = "qcom,pm8941-rtc";
					reg = <0x6000 0x6100>;
					reg-names = "rtc\0alarm";
					interrupts = <0x00 0x61 0x01 0x01>;
				};

				pon@800 {
					compatible = "qcom,pm8916-pon";
					reg = <0x800>;
					mode-bootloader = <0x02>;
					mode-recovery = <0x01>;

					pwrkey {
						compatible = "qcom,pm8941-pwrkey";
						interrupts = <0x00 0x08 0x00 0x03>;
						debounce = <0x3d09>;
						bias-pull-up;
						linux,code = <0x74>;
					};

					resin {
						compatible = "qcom,pm8941-resin";
						interrupts = <0x00 0x08 0x01 0x03>;
						debounce = <0x3d09>;
						bias-pull-up;
						linux,code = <0x72>;
					};
				};

				gpios@c000 {
					compatible = "qcom,pm8994-gpio";
					reg = <0xc000>;
					gpio-controller;
					#gpio-cells = <0x02>;
					interrupts = <0x00 0xc0 0x00 0x00 0x00 0xc1 0x00 0x00 0x00 0xc2 0x00 0x00 0x00 0xc3 0x00 0x00 0x00 0xc4 0x00 0x00 0x00 0xc5 0x00 0x00 0x00 0xc6 0x00 0x00 0x00 0xc7 0x00 0x00 0x00 0xc8 0x00 0x00 0x00 0xc9 0x00 0x00 0x00 0xca 0x00 0x00 0x00 0xcb 0x00 0x00 0x00 0xcc 0x00 0x00 0x00 0xcd 0x00 0x00 0x00 0xce 0x00 0x00 0x00 0xcf 0x00 0x00 0x00 0xd0 0x00 0x00 0x00 0xd1 0x00 0x00 0x00 0xd2 0x00 0x00 0x00 0xd3 0x00 0x00 0x00 0xd4 0x00 0x00 0x00 0xd5 0x00 0x00>;
					pinctrl-names = "default";
					pinctrl-0 = <0x54 0x55>;
					gpio-line-names = "NC\0KEY_VOLP_N\0NC\0BL1_PWM\0GPIO-F\0BL1_EN\0NC\0WLAN_EN\0NC\0NC\0NC\0NC\0NC\0NC\0DIVCLK1\0DIVCLK2\0DIVCLK3\0DIVCLK4\0BT_EN\0PMIC_SLB\0PMIC_BUA\0USB_VBUS_DET";
					phandle = <0x0e>;

					pm8994_gpio5 {
						phandle = <0x54>;

						pinconf {
							pins = "gpio5";
							output-low;
							power-source = <0x02>;
						};
					};

					bt_en_gpios {
						phandle = <0x55>;

						pinconf {
							pins = "gpio19";
							function = "normal";
							output-low;
							power-source = <0x02>;
							qcom,drive-strength = <0x03>;
							bias-pull-down;
						};
					};

					wlan_en_gpios {
						phandle = <0x92>;

						pinconf {
							pins = "gpio8";
							function = "normal";
							output-low;
							power-source = <0x02>;
							qcom,drive-strength = <0x03>;
							bias-pull-down;
						};
					};

					clk_div1 {
						phandle = <0x0c>;

						pinconf {
							pins = "gpio15";
							function = "func1";
							power-source = <0x02>;
						};
					};

					pm8996_gpio2 {
						phandle = <0x9c>;

						pinconf {
							pins = "gpio2";
							function = "normal";
							input-enable;
							drive-push-pull;
							bias-pull-up;
							qcom,drive-strength = <0x00>;
							power-source = <0x02>;
						};
					};

					divclk4 {
						phandle = <0x0b>;

						pinconf {
							pins = "gpio18";
							function = "func2";
							bias-disable;
							power-source = <0x02>;
						};
					};

					pm8996_gpio22 {
						phandle = <0x90>;

						pinconf {
							pins = "gpio22";
							function = "normal";
							input-enable;
							bias-pull-down;
							qcom,drive-strength = <0x00>;
							power-source = <0x02>;
						};
					};
				};

				mpps@a000 {
					compatible = "qcom,pm8994-mpp";
					reg = <0xa000>;
					gpio-controller;
					#gpio-cells = <0x02>;
					interrupts = <0x00 0xa0 0x00 0x00 0x00 0xa1 0x00 0x00 0x00 0xa2 0x00 0x00 0x00 0xa3 0x00 0x00 0x00 0xa4 0x00 0x00 0x00 0xa5 0x00 0x00 0x00 0xa6 0x00 0x00 0x00 0xa7 0x00 0x00>;
					gpio-line-names = "VDDPX_BIAS\0WIFI_LED\0NC\0BT_LED\0PM_MPP05\0PM_MPP06\0PM_MPP07\0NC";
					phandle = <0xf2>;
				};
			};

			pmic@1 {
				compatible = "qcom,pm8994\0qcom,spmi-pmic";
				reg = <0x01 0x00>;
				#address-cells = <0x01>;
				#size-cells = <0x00>;
			};

			pmic@2 {
				compatible = "qcom,pmi8994\0qcom,spmi-pmic";
				reg = <0x02 0x00>;
				#address-cells = <0x01>;
				#size-cells = <0x00>;

				gpios@c000 {
					compatible = "qcom,pmi8994-gpio\0qcom,spmi-gpio";
					reg = <0xc000>;
					gpio-controller;
					gpio-ranges = <0x56 0x00 0x00 0x0a>;
					#gpio-cells = <0x02>;
					interrupt-controller;
					#interrupt-cells = <0x02>;
					gpio-line-names = "NC\0SPKR_AMP_EN1\0SPKR_AMP_EN2\0TP61\0NC\0USB2_VBUS_DET\0NC\0NC\0NC\0NC";
					phandle = <0x56>;

					pmi8996_gpio6 {
						phandle = <0x91>;

						pinconf {
							pins = "gpio6";
							function = "normal";
							input-enable;
							bias-pull-down;
							qcom,drive-strength = <0x00>;
							power-source = <0x02>;
						};
					};
				};
			};

			pmic@3 {
				compatible = "qcom,pmi8994\0qcom,spmi-pmic";
				reg = <0x03 0x00>;
				#address-cells = <0x01>;
				#size-cells = <0x00>;
			};
		};

		phy@627000 {
			compatible = "qcom,msm8996-ufs-phy-qmp-14nm";
			reg = <0x627000 0xda8>;
			reg-names = "phy_mem";
			#phy-cells = <0x00>;
			vdda-phy-supply = <0x57>;
			vdda-pll-supply = <0x58>;
			vdda-phy-max-microamp = <0x47cc>;
			vdda-pll-max-microamp = <0x24e0>;
			vddp-ref-clk-supply = <0x59>;
			vddp-ref-clk-max-microamp = <0x64>;
			vddp-ref-clk-always-on;
			clock-names = "ref_clk_src\0ref_clk";
			clocks = <0x0d 0x4a 0x18 0xd7>;
			resets = <0x5a 0x00>;
			status = "okay";
			phandle = <0x5b>;
		};

		ufshc@624000 {
			compatible = "qcom,ufshc";
			reg = <0x624000 0x2500>;
			interrupts = <0x00 0x109 0x04>;
			phys = <0x5b>;
			phy-names = "ufsphy";
			vcc-supply = <0x5c>;
			vccq-supply = <0x59>;
			vccq2-supply = <0x5d>;
			vcc-max-microamp = <0x927c0>;
			vccq-max-microamp = <0x6ddd0>;
			vccq2-max-microamp = <0x6ddd0>;
			power-domains = <0x18 0x08>;
			clock-names = "core_clk_src\0core_clk\0bus_clk\0bus_aggr_clk\0iface_clk\0core_clk_unipro_src\0core_clk_unipro\0core_clk_ice\0ref_clk\0tx_lane0_sync_clk\0rx_lane0_sync_clk";
			clocks = <0x18 0x49 0x18 0xc1 0x18 0x52 0x18 0xd1 0x18 0xc2 0x18 0x4a 0x18 0xc8 0x18 0xc9 0x0d 0x4a 0x18 0xc5 0x18 0xc6>;
			freq-table-hz = <0x5f5e100 0xbebc200 0x00 0x00 0x00 0x00 0x00 0x00 0x00 0x00 0x8f0d180 0x11e1a300 0x00 0x00 0x00 0x00 0x00 0x00 0x00 0x00 0x00 0x00>;
			lanes-per-direction = <0x01>;
			#reset-cells = <0x01>;
			status = "okay";
			phandle = <0x5a>;

			ufs_variant {
				compatible = "qcom,ufs_variant";
			};
		};

		clock-controller@8c0000 {
			compatible = "qcom,mmcc-msm8996";
			#clock-cells = <0x01>;
			#reset-cells = <0x01>;
			#power-domain-cells = <0x01>;
			reg = <0x8c0000 0x40000>;
			assigned-clocks = <0x5e 0x0f 0x5e 0x03 0x5e 0x07 0x5e 0x09 0x5e 0x0b>;
			assigned-clock-rates = <0x25317c00 0x30479e80 0x3a699d00 0x39387000 0x312c8040>;
			phandle = <0x5e>;
		};

		qfprom@74000 {
			compatible = "qcom,qfprom";
			reg = <0x74000 0x8ff>;
			#address-cells = <0x01>;
			#size-cells = <0x01>;

			hstx_trim@24e {
				reg = <0x24e 0x02>;
				bits = <0x05 0x04>;
				phandle = <0x60>;
			};

			hstx_trim@24f {
				reg = <0x24f 0x01>;
				bits = <0x01 0x04>;
				phandle = <0x61>;
			};

			gpu_speed_bin@133 {
				reg = <0x133 0x01>;
				bits = <0x05 0x03>;
				phandle = <0x82>;
			};
		};

		phy@34000 {
			compatible = "qcom,msm8996-qmp-pcie-phy";
			reg = <0x34000 0x488>;
			#clock-cells = <0x01>;
			#address-cells = <0x01>;
			#size-cells = <0x01>;
			ranges;
			clocks = <0x18 0xc0 0x18 0xbf 0x18 0xd8>;
			clock-names = "aux\0cfg_ahb\0ref";
			vdda-phy-supply = <0x57>;
			vdda-pll-supply = <0x58>;
			resets = <0x18 0x55 0x18 0x65 0x18 0x66>;
			reset-names = "phy\0common\0cfg";
			status = "okay";

			lane@35000 {
				reg = <0x35000 0x130 0x35200 0x200 0x35400 0x1dc>;
				#phy-cells = <0x00>;
				clock-output-names = "pcie_0_pipe_clk_src";
				clocks = <0x18 0xb4>;
				clock-names = "pipe0";
				resets = <0x18 0x50>;
				reset-names = "lane0";
				phandle = <0x69>;
			};

			lane@36000 {
				reg = <0x36000 0x130 0x36200 0x200 0x36400 0x1dc>;
				#phy-cells = <0x00>;
				clock-output-names = "pcie_1_pipe_clk_src";
				clocks = <0x18 0xb9>;
				clock-names = "pipe1";
				resets = <0x18 0x52>;
				reset-names = "lane1";
				phandle = <0x70>;
			};

			lane@37000 {
				reg = <0x37000 0x130 0x37200 0x200 0x37400 0x1dc>;
				#phy-cells = <0x00>;
				clock-output-names = "pcie_2_pipe_clk_src";
				clocks = <0x18 0xbe>;
				clock-names = "pipe2";
				resets = <0x18 0x54>;
				reset-names = "lane2";
				phandle = <0x76>;
			};
		};

		phy@7410000 {
			compatible = "qcom,msm8996-qmp-usb3-phy";
			reg = <0x7410000 0x1c4>;
			#clock-cells = <0x01>;
			#address-cells = <0x01>;
			#size-cells = <0x01>;
			ranges;
			clocks = <0x18 0x5e 0x18 0x63 0x18 0xd5>;
			clock-names = "aux\0cfg_ahb\0ref";
			vdda-phy-supply = <0x57>;
			vdda-pll-supply = <0x58>;
			resets = <0x18 0x67 0x18 0x68>;
			reset-names = "phy\0common";
			status = "okay";

			lane@7410200 {
				reg = <0x7410200 0x200 0x7410400 0x130 0x7410600 0x1a8>;
				#phy-cells = <0x00>;
				clock-output-names = "usb3_phy_pipe_clk_src";
				clocks = <0x18 0x5f>;
				clock-names = "pipe0";
				phandle = <0x66>;
			};
		};

		phy@7411000 {
			compatible = "qcom,msm8996-qusb2-phy";
			reg = <0x7411000 0x180>;
			#phy-cells = <0x00>;
			clocks = <0x18 0x63 0x18 0xda>;
			clock-names = "cfg_ahb\0ref";
			vdda-pll-supply = <0x58>;
			vdda-phy-dpdm-supply = <0x5f>;
			resets = <0x18 0x09>;
			nvmem-cells = <0x60>;
			status = "okay";
			phandle = <0x65>;
		};

		phy@7412000 {
			compatible = "qcom,msm8996-qusb2-phy";
			reg = <0x7412000 0x180>;
			#phy-cells = <0x00>;
			clocks = <0x18 0x63 0x18 0xd9>;
			clock-names = "cfg_ahb\0ref";
			vdda-pll-supply = <0x58>;
			vdda-phy-dpdm-supply = <0x5f>;
			resets = <0x18 0x0a>;
			nvmem-cells = <0x61>;
			status = "okay";
			phandle = <0x63>;
		};

		usb@76f8800 {
			compatible = "qcom,msm8996-dwc3\0qcom,dwc3";
			reg = <0x76f8800 0x400>;
			#address-cells = <0x01>;
			#size-cells = <0x01>;
			ranges;
			clocks = <0x18 0x55 0x18 0x60 0x18 0x62 0x18 0x61 0x18 0x63>;
			assigned-clocks = <0x18 0x62 0x18 0x60>;
			assigned-clock-rates = <0x124f800 0x3938700>;
			power-domains = <0x18 0x04>;
			status = "okay";
			extcon = <0x62>;
			phandle = <0xf3>;

			dwc3@7600000 {
				compatible = "snps,dwc3";
				reg = <0x7600000 0xcc00>;
				interrupts = <0x00 0x8a 0x04>;
				phys = <0x63>;
				phy-names = "usb2-phy";
				snps,dis_u2_susphy_quirk;
				snps,dis_enblslpm_quirk;
				extcon = <0x62>;
				dr_mode = "otg";
				maximum-speed = "high-speed";
			};
		};

		usb@6af8800 {
			compatible = "qcom,msm8996-dwc3\0qcom,dwc3";
			reg = <0x6af8800 0x400>;
			#address-cells = <0x01>;
			#size-cells = <0x01>;
			ranges;
			clocks = <0x18 0x51 0x18 0x5b 0x18 0xd2 0x18 0x5d 0x18 0x5c 0x18 0x63>;
			assigned-clocks = <0x18 0x5d 0x18 0x5b>;
			assigned-clock-rates = <0x124f800 0x7270e00>;
			power-domains = <0x18 0x04>;
			status = "okay";
			extcon = <0x64>;
			phandle = <0xf4>;

			dwc3@6a00000 {
				compatible = "snps,dwc3";
				reg = <0x6a00000 0xcc00>;
				interrupts = <0x00 0x83 0x04>;
				phys = <0x65 0x66>;
				phy-names = "usb2-phy\0usb3-phy";
				snps,dis_u2_susphy_quirk;
				snps,dis_enblslpm_quirk;
				extcon = <0x64>;
				dr_mode = "otg";
			};
		};

		iommu@da0000 {
			compatible = "qcom,msm8996-smmu-v2\0qcom,smmu-v2";
			reg = <0xda0000 0x10000>;
			#global-interrupts = <0x01>;
			interrupts = <0x00 0x4c 0x04 0x00 0x157 0x04 0x00 0x158 0x04>;
			power-domains = <0x5e 0x02>;
			clocks = <0x5e 0x4e 0x5e 0x4f>;
			clock-names = "iface\0bus";
			#iommu-cells = <0x01>;
			phandle = <0x68>;
		};

		camss@a00000 {
			compatible = "qcom,msm8996-camss";
			reg = <0xa34000 0x1000 0xa00030 0x04 0xa35000 0x1000 0xa00038 0x04 0xa36000 0x1000 0xa00040 0x04 0xa30000 0x100 0xa30400 0x100 0xa30800 0x100 0xa30c00 0x100 0xa31000 0x500 0xa00020 0x10 0xa10000 0x1000 0xa14000 0x1000>;
			reg-names = "csiphy0\0csiphy0_clk_mux\0csiphy1\0csiphy1_clk_mux\0csiphy2\0csiphy2_clk_mux\0csid0\0csid1\0csid2\0csid3\0ispif\0csi_clk_mux\0vfe0\0vfe1";
			interrupts = <0x00 0x4e 0x01 0x00 0x4f 0x01 0x00 0x50 0x01 0x00 0x128 0x01 0x00 0x129 0x01 0x00 0x12a 0x01 0x00 0x12b 0x01 0x00 0x135 0x01 0x00 0x13a 0x01 0x00 0x13b 0x01>;
			interrupt-names = "csiphy0\0csiphy1\0csiphy2\0csid0\0csid1\0csid2\0csid3\0ispif\0vfe0\0vfe1";
			power-domains = <0x5e 0x08>;
			clocks = <0x5e 0x81 0x5e 0xb9 0x5e 0x8c 0x5e 0x8d 0x5e 0x8e 0x5e 0xa6 0x5e 0xa5 0x5e 0xa7 0x5e 0xa9 0x5e 0xa8 0x5e 0xab 0x5e 0xaa 0x5e 0xac 0x5e 0xae 0x5e 0xad 0x5e 0xb0 0x5e 0xaf 0x5e 0xb1 0x5e 0xb3 0x5e 0xb2 0x5e 0xb5 0x5e 0xb4 0x5e 0xb6 0x5e 0xb8 0x5e 0xb7 0x5e 0x82 0x5e 0x99 0x5e 0x9f 0x5e 0x9b 0x5e 0x9a 0x5e 0x9c 0x5e 0xa0 0x5e 0x9e 0x5e 0x9d 0x5e 0x97 0x5e 0x98>;
			clock-names = "top_ahb\0ispif_ahb\0csiphy0_timer\0csiphy1_timer\0csiphy2_timer\0csi0_ahb\0csi0\0csi0_phy\0csi0_pix\0csi0_rdi\0csi1_ahb\0csi1\0csi1_phy\0csi1_pix\0csi1_rdi\0csi2_ahb\0csi2\0csi2_phy\0csi2_pix\0csi2_rdi\0csi3_ahb\0csi3\0csi3_phy\0csi3_pix\0csi3_rdi\0ahb\0vfe0\0csi_vfe0\0vfe0_ahb\0vfe0_stream\0vfe1\0csi_vfe1\0vfe1_ahb\0vfe1_stream\0vfe_ahb\0vfe_axi";
			vdda-supply = <0x67>;
			iommus = <0x68 0x00 0x68 0x01 0x68 0x02 0x68 0x03>;
			status = "disabled";
			phandle = <0xf5>;

			ports {
				#address-cells = <0x01>;
				#size-cells = <0x00>;
			};
		};

		iommu@b40000 {
			compatible = "qcom,msm8996-smmu-v2\0qcom,smmu-v2";
			reg = <0xb40000 0x10000>;
			#global-interrupts = <0x01>;
			interrupts = <0x00 0x14e 0x04 0x00 0x149 0x04 0x00 0x14a 0x04>;
			#iommu-cells = <0x01>;
			clocks = <0x5e 0x68 0x18 0x5a>;
			clock-names = "iface\0bus";
			power-domains = <0x5e 0x03>;
			phandle = <0x81>;
		};

		iommu@d00000 {
			compatible = "qcom,msm8996-smmu-v2\0qcom,smmu-v2";
			reg = <0xd00000 0x10000>;
			#global-interrupts = <0x01>;
			interrupts = <0x00 0x49 0x04 0x00 0x140 0x04 0x00 0x141 0x04>;
			#iommu-cells = <0x01>;
			clocks = <0x5e 0x5b 0x5e 0x5c>;
			clock-names = "iface\0bus";
			power-domains = <0x5e 0x0d>;
			phandle = <0x86>;
		};

		iommu@1600000 {
			compatible = "qcom,msm8996-smmu-v2\0qcom,smmu-v2";
			reg = <0x1600000 0x20000>;
			#iommu-cells = <0x01>;
			power-domains = <0x18 0x03>;
			#global-interrupts = <0x01>;
			interrupts = <0x00 0x194 0x04 0x00 0xe2 0x04 0x00 0x189 0x04 0x00 0x18a 0x04 0x00 0x18b 0x04 0x00 0x18c 0x04 0x00 0x18d 0x04 0x00 0x18e 0x04 0x00 0x18f 0x04 0x00 0x190 0x04 0x00 0x191 0x04 0x00 0x192 0x04 0x00 0x193 0x04>;
			clocks = <0x18 0xdb 0x18 0xdc>;
			clock-names = "iface\0bus";
			phandle = <0x9b>;
		};

		agnoc@0 {
			power-domains = <0x18 0x00>;
			compatible = "simple-pm-bus";
			#address-cells = <0x01>;
			#size-cells = <0x01>;
			ranges;

			pcie@600000 {
				compatible = "qcom,pcie-msm8996\0snps,dw-pcie";
				status = "okay";
				power-domains = <0x18 0x05>;
				bus-range = <0x00 0xff>;
				num-lanes = <0x01>;
				reg = <0x600000 0x2000 0xc000000 0xf1d 0xc000f20 0xa8 0xc100000 0x100000>;
				reg-names = "parf\0dbi\0elbi\0config";
				phys = <0x69>;
				phy-names = "pciephy";
				#address-cells = <0x03>;
				#size-cells = <0x02>;
				ranges = <0x1000000 0x00 0xc200000 0xc200000 0x00 0x100000 0x2000000 0x00 0xc300000 0xc300000 0x00 0xd00000>;
				interrupts = <0x00 0x195 0x04>;
				interrupt-names = "msi";
				#interrupt-cells = <0x01>;
				interrupt-map-mask = <0x00 0x00 0x00 0x07>;
				interrupt-map = <0x00 0x00 0x00 0x01 0x01 0x00 0xf4 0x04 0x00 0x00 0x00 0x02 0x01 0x00 0xf5 0x04 0x00 0x00 0x00 0x03 0x01 0x00 0xf7 0x04 0x00 0x00 0x00 0x04 0x01 0x00 0xf8 0x04>;
				pinctrl-names = "default\0sleep";
				pinctrl-0 = <0x6a 0x6b 0x6c>;
				pinctrl-1 = <0x6d 0x6b 0x6e>;
				vdda-supply = <0x57>;
				linux,pci-domain = <0x00>;
				clocks = <0x18 0xb4 0x18 0xb3 0x18 0xb2 0x18 0xb1 0x18 0xb0>;
				clock-names = "pipe\0aux\0cfg\0bus_master\0bus_slave";
				perst-gpio = <0x51 0x23 0x01>;
				vddpe-3v3-supply = <0x6f>;
				phandle = <0xf6>;
			};

			pcie@608000 {
				compatible = "qcom,pcie-msm8996\0snps,dw-pcie";
				power-domains = <0x18 0x06>;
				bus-range = <0x00 0xff>;
				num-lanes = <0x01>;
				status = "okay";
				reg = <0x608000 0x2000 0xd000000 0xf1d 0xd000f20 0xa8 0xd100000 0x100000>;
				reg-names = "parf\0dbi\0elbi\0config";
				phys = <0x70>;
				phy-names = "pciephy";
				#address-cells = <0x03>;
				#size-cells = <0x02>;
				ranges = <0x1000000 0x00 0xd200000 0xd200000 0x00 0x100000 0x2000000 0x00 0xd300000 0xd300000 0x00 0xd00000>;
				interrupts = <0x00 0x19d 0x04>;
				interrupt-names = "msi";
				#interrupt-cells = <0x01>;
				interrupt-map-mask = <0x00 0x00 0x00 0x07>;
				interrupt-map = <0x00 0x00 0x00 0x01 0x01 0x00 0x110 0x04 0x00 0x00 0x00 0x02 0x01 0x00 0x111 0x04 0x00 0x00 0x00 0x03 0x01 0x00 0x112 0x04 0x00 0x00 0x00 0x04 0x01 0x00 0x113 0x04>;
				pinctrl-names = "default\0sleep";
				pinctrl-0 = <0x71 0x72 0x73>;
				pinctrl-1 = <0x74 0x72 0x75>;
				vdda-supply = <0x57>;
				linux,pci-domain = <0x01>;
				clocks = <0x18 0xb9 0x18 0xb8 0x18 0xb7 0x18 0xb6 0x18 0xb5>;
				clock-names = "pipe\0aux\0cfg\0bus_master\0bus_slave";
				perst-gpio = <0x51 0x82 0x01>;
				phandle = <0xf7>;
			};

			pcie@610000 {
				compatible = "qcom,pcie-msm8996\0snps,dw-pcie";
				power-domains = <0x18 0x07>;
				bus-range = <0x00 0xff>;
				num-lanes = <0x01>;
				status = "okay";
				reg = <0x610000 0x2000 0xe000000 0xf1d 0xe000f20 0xa8 0xe100000 0x100000>;
				reg-names = "parf\0dbi\0elbi\0config";
				phys = <0x76>;
				phy-names = "pciephy";
				#address-cells = <0x03>;
				#size-cells = <0x02>;
				ranges = <0x1000000 0x00 0xe200000 0xe200000 0x00 0x100000 0x2000000 0x00 0xe300000 0xe300000 0x00 0x1d00000>;
				device_type = "pci";
				interrupts = <0x00 0x1a5 0x04>;
				interrupt-names = "msi";
				#interrupt-cells = <0x01>;
				interrupt-map-mask = <0x00 0x00 0x00 0x07>;
				interrupt-map = <0x00 0x00 0x00 0x01 0x01 0x00 0x8e 0x04 0x00 0x00 0x00 0x02 0x01 0x00 0x8f 0x04 0x00 0x00 0x00 0x03 0x01 0x00 0x90 0x04 0x00 0x00 0x00 0x04 0x01 0x00 0x91 0x04>;
				pinctrl-names = "default\0sleep";
				pinctrl-0 = <0x77 0x78 0x79>;
				pinctrl-1 = <0x7a 0x78 0x7b>;
				vdda-supply = <0x57>;
				linux,pci-domain = <0x02>;
				clocks = <0x18 0xbe 0x18 0xbd 0x18 0xbc 0x18 0xbb 0x18 0xba>;
				clock-names = "pipe\0aux\0cfg\0bus_master\0bus_slave";
				perst-gpio = <0x51 0x72 0x01>;
				phandle = <0xf8>;
			};
		};

		dma@9184000 {
			compatible = "qcom,bam-v1.7.0";
			qcom,controlled-remotely;
			reg = <0x9184000 0x32000>;
			num-channels = <0x1f>;
			interrupts = <0x00 0xa4 0x04>;
			#dma-cells = <0x01>;
			qcom,ee = <0x01>;
			qcom,num-ees = <0x02>;
			phandle = <0x7c>;
		};

		slim@91c0000 {
			compatible = "qcom,slim-ngd-v1.5.0";
			reg = <0x91c0000 0x2c000>;
			reg-names = "ctrl";
			interrupts = <0x00 0xa3 0x04>;
			dmas = <0x7c 0x03 0x7c 0x04 0x7c 0x05 0x7c 0x06>;
			dma-names = "rx\0tx\0tx2\0rx2";
			#address-cells = <0x01>;
			#size-cells = <0x00>;
			phandle = <0xf9>;

			ngd@1 {
				reg = <0x01>;
				#address-cells = <0x01>;
				#size-cells = <0x01>;

				tas-ifd {
					compatible = "slim217,1a0";
					reg = <0x00 0x00>;
					phandle = <0x7f>;
				};

				codec@1 {
					pinctrl-0 = <0x7d 0x7e>;
					pinctrl-names = "default";
					compatible = "slim217,1a0";
					reg = <0x01 0x00>;
					interrupt-parent = <0x51>;
					interrupts = <0x36 0x04 0x35 0x04>;
					interrupt-names = "intr1\0intr2";
					interrupt-controller;
					#interrupt-cells = <0x01>;
					reset-gpios = <0x51 0x40 0x00>;
					slim-ifc-dev = <0x7f>;
					vdd-buck-supply = <0x5d>;
					vdd-buck-sido-supply = <0x5d>;
					vdd-tx-supply = <0x5d>;
					vdd-rx-supply = <0x5d>;
					vdd-io-supply = <0x5d>;
					#sound-dai-cells = <0x01>;
					clock-names = "mclk\0slimbus";
					clocks = <0x80 0x0d 0x0a>;
					phandle = <0x97>;
				};
			};
		};

		gpu@b00000 {
			compatible = "qcom,adreno-530.2\0qcom,adreno";
			#stream-id-cells = <0x10>;
			reg = <0xb00000 0x3f000>;
			reg-names = "kgsl_3d0_reg_memory";
			interrupts = <0x00 0x12c 0x04>;
			clocks = <0x5e 0x66 0x5e 0x68 0x5e 0x67 0x18 0xa8 0x18 0x5a>;
			clock-names = "core\0iface\0rbbmtimer\0mem\0mem_iface";
			power-domains = <0x5e 0x03>;
			iommus = <0x81 0x00>;
			nvmem-cells = <0x82>;
			nvmem-cell-names = "speed_bin";
			operating-points-v2 = <0x83>;

			opp-table {
				compatible = "operating-points-v2";
				phandle = <0x83>;

				opp-624000000 {
					opp-hz = <0x00 0x25317c00>;
					opp-supported-hw = <0x01>;
				};

				opp-560000000 {
					opp-hz = <0x00 0x2160ec00>;
					opp-supported-hw = <0x01>;
				};

				opp-510000000 {
					opp-hz = <0x00 0x1e65fb80>;
					opp-supported-hw = <0xff>;
				};

				opp-401800000 {
					opp-hz = <0x00 0x17f2fb40>;
					opp-supported-hw = <0xff>;
				};

				opp-315000000 {
					opp-hz = <0x00 0x12c684c0>;
					opp-supported-hw = <0xff>;
				};

				opp-214000000 {
					opp-hz = <0x00 0xcc16180>;
					opp-supported-hw = <0xff>;
				};

				opp-133000000 {
					opp-hz = <0x00 0x7ed6b40>;
					opp-supported-hw = <0xff>;
				};
			};

			zap-shader {
				memory-region = <0x84>;
			};
		};

		mdss@900000 {
			compatible = "qcom,mdss";
			reg = <0x900000 0x1000 0x9b0000 0x1040 0x9b8000 0x1040>;
			reg-names = "mdss_phys\0vbif_phys\0vbif_nrt_phys";
			power-domains = <0x5e 0x0d>;
			interrupts = <0x00 0x53 0x04>;
			interrupt-controller;
			#interrupt-cells = <0x01>;
			clocks = <0x5e 0x74>;
			clock-names = "iface";
			#address-cells = <0x01>;
			#size-cells = <0x01>;
			ranges;
			status = "okay";
			phandle = <0x85>;

			mdp@901000 {
				compatible = "qcom,mdp5";
				reg = <0x901000 0x90000>;
				reg-names = "mdp_phys";
				interrupt-parent = <0x85>;
				interrupts = <0x00 0x04>;
				clocks = <0x5e 0x74 0x5e 0x76 0x5e 0x79 0x5e 0x5c 0x5e 0x7b>;
				clock-names = "iface\0bus\0core\0iommu\0vsync";
				iommus = <0x86 0x00>;
				status = "okay";
				phandle = <0xfa>;

				ports {
					#address-cells = <0x01>;
					#size-cells = <0x00>;

					port@0 {
						reg = <0x00>;

						endpoint {
							remote-endpoint = <0x87>;
							phandle = <0x8d>;
						};
					};
				};
			};

			hdmi-tx@9a0000 {
				compatible = "qcom,hdmi-tx-8996";
				reg = <0x9a0000 0x50c 0x70000 0x6158 0x9e0000 0xfff>;
				reg-names = "core_physical\0qfprom_physical\0hdcp_physical";
				interrupt-parent = <0x85>;
				interrupts = <0x08 0x04>;
				clocks = <0x5e 0x79 0x5e 0x74 0x5e 0x7c 0x5e 0x75 0x5e 0x7a>;
				clock-names = "mdp_core\0iface\0core\0alt_iface\0extp";
				phys = <0x88>;
				phy-names = "hdmi_phy";
				#sound-dai-cells = <0x01>;
				status = "okay";
				pinctrl-names = "default\0sleep";
				pinctrl-0 = <0x89 0x8a>;
				pinctrl-1 = <0x8b 0x8c>;
				core-vdda-supply = <0x58>;
				core-vcc-supply = <0x5d>;
				phandle = <0x96>;

				ports {
					#address-cells = <0x01>;
					#size-cells = <0x00>;

					port@0 {
						reg = <0x00>;

						endpoint {
							remote-endpoint = <0x8d>;
							phandle = <0x87>;
						};
					};
				};
			};

			hdmi-phy@9a0600 {
				#phy-cells = <0x00>;
				compatible = "qcom,hdmi-phy-8996";
				reg = <0x9a0600 0x1c4 0x9a0a00 0x124 0x9a0c00 0x124 0x9a0e00 0x124 0x9a1000 0x124 0x9a1200 0xc8>;
				reg-names = "hdmi_pll\0hdmi_tx_l0\0hdmi_tx_l1\0hdmi_tx_l2\0hdmi_tx_l3\0hdmi_phy";
				clocks = <0x5e 0x74 0x18 0xd6>;
				clock-names = "iface\0ref";
				status = "okay";
				vddio-supply = <0x58>;
				vcca-supply = <0x57>;
				phandle = <0x88>;
			};
		};

		arm,smmu-venus@d40000 {
			compatible = "qcom,msm8996-smmu-v2\0qcom,smmu-v2";
			reg = <0xd40000 0x20000>;
			#global-interrupts = <0x01>;
			interrupts = <0x00 0x11e 0x04 0x00 0x14f 0x04 0x00 0x150 0x04 0x00 0x151 0x04 0x00 0x152 0x04 0x00 0x153 0x04 0x00 0x154 0x04 0x00 0x155 0x04>;
			power-domains = <0x5e 0x00>;
			clocks = <0x5e 0x62 0x5e 0x63>;
			clock-names = "iface\0bus";
			#iommu-cells = <0x01>;
			status = "okay";
			phandle = <0x8e>;
		};

		video-codec@c00000 {
			compatible = "qcom,msm8996-venus";
			reg = <0xc00000 0xff000>;
			interrupts = <0x00 0x11f 0x04>;
			power-domains = <0x5e 0x04>;
			clocks = <0x5e 0x6e 0x5e 0x71 0x5e 0x6f 0x5e 0x70>;
			clock-names = "core\0iface\0bus\0mbus";
			iommus = <0x8e 0x00 0x8e 0x01 0x8e 0x0a 0x8e 0x07 0x8e 0x0e 0x8e 0x0f 0x8e 0x08 0x8e 0x09 0x8e 0x0b 0x8e 0x0c 0x8e 0x0d 0x8e 0x10 0x8e 0x11 0x8e 0x21 0x8e 0x28 0x8e 0x29 0x8e 0x2b 0x8e 0x2c 0x8e 0x2d 0x8e 0x31>;
			memory-region = <0x8f>;
			status = "okay";

			video-decoder {
				compatible = "venus-decoder";
				clocks = <0x5e 0x72>;
				clock-names = "core";
				power-domains = <0x5e 0x05>;
			};

			video-encoder {
				compatible = "venus-encoder";
				clocks = <0x5e 0x73>;
				clock-names = "core";
				power-domains = <0x5e 0x06>;
			};
		};

		usb3-id {
			compatible = "linux,extcon-usb-gpio";
			id-gpio = <0x0e 0x16 0x00>;
			pinctrl-names = "default";
			pinctrl-0 = <0x90>;
			phandle = <0x64>;
		};

		usb2-id {
			compatible = "linux,extcon-usb-gpio";
			id-gpio = <0x56 0x06 0x00>;
			pinctrl-names = "default";
			pinctrl-0 = <0x91>;
			phandle = <0x62>;
		};

		wlan-en-1-8v {
			pinctrl-names = "default";
			pinctrl-0 = <0x92>;
			compatible = "regulator-fixed";
			regulator-name = "wlan-en-regulator";
			regulator-min-microvolt = <0x1b7740>;
			regulator-max-microvolt = <0x1b7740>;
			gpio = <0x0e 0x08 0x00>;
			startup-delay-us = <0x11170>;
			enable-active-high;
			phandle = <0x6f>;
		};
	};

	sound {
		compatible = "qcom,apq8096-sndcard";
		model = "DB820c";
		audio-routing = "RX_BIAS\0MCLK";
		phandle = <0xfb>;

		mm1-dai-link {
			link-name = "MultiMedia1";

			cpu {
				sound-dai = <0x93 0x00>;
			};
		};

		mm2-dai-link {
			link-name = "MultiMedia2";

			cpu {
				sound-dai = <0x93 0x01>;
			};
		};

		mm3-dai-link {
			link-name = "MultiMedia3";

			cpu {
				sound-dai = <0x93 0x02>;
			};
		};

		hdmi-dai-link {
			link-name = "HDMI";

			cpu {
				sound-dai = <0x94 0x01>;
			};

			platform {
				sound-dai = <0x95>;
			};

			codec {
				sound-dai = <0x96 0x00>;
			};
		};

		slim-dai-link {
			link-name = "SLIM Playback";

			cpu {
				sound-dai = <0x94 0x0e>;
			};

			platform {
				sound-dai = <0x95>;
			};

			codec {
				sound-dai = <0x97 0x06>;
			};
		};

		slimcap-dai-link {
			link-name = "SLIM Capture";

			cpu {
				sound-dai = <0x94 0x03>;
			};

			platform {
				sound-dai = <0x95>;
			};

			codec {
				sound-dai = <0x97 0x01>;
			};
		};
	};

	adsp-pil {
		compatible = "qcom,msm8996-adsp-pil";
		interrupts-extended = <0x01 0x00 0xa2 0x01 0x98 0x00 0x01 0x98 0x01 0x01 0x98 0x02 0x01 0x98 0x03 0x01>;
		interrupt-names = "wdog\0fatal\0ready\0handover\0stop-ack";
		clocks = <0x48>;
		clock-names = "xo";
		memory-region = <0x99>;
		qcom,smem-states = <0x9a 0x00>;
		qcom,smem-state-names = "stop";

		smd-edge {
			interrupts = <0x00 0x9c 0x01>;
			label = "lpass";
			mboxes = <0x14 0x08>;
			qcom,smd-edge = <0x01>;
			qcom,remote-pid = <0x02>;
			#address-cells = <0x01>;
			#size-cells = <0x00>;

			apr {
				power-domains = <0x18 0x02>;
				compatible = "qcom,apr-v2";
				qcom,smd-channels = "apr_audio_svc";
				qcom,apr-domain = <0x04>;
				#address-cells = <0x01>;
				#size-cells = <0x00>;

				q6core {
					reg = <0x03>;
					compatible = "qcom,q6core";
				};

				q6afe {
					compatible = "qcom,q6afe";
					reg = <0x04>;
					phandle = <0xfc>;

					dais {
						compatible = "qcom,q6afe-dais";
						#address-cells = <0x01>;
						#size-cells = <0x00>;
						#sound-dai-cells = <0x01>;
						phandle = <0x94>;

						hdmi@1 {
							reg = <0x01>;
						};
					};
				};

				q6asm {
					compatible = "qcom,q6asm";
					reg = <0x07>;
					phandle = <0xfd>;

					dais {
						compatible = "qcom,q6asm-dais";
						#sound-dai-cells = <0x01>;
						iommus = <0x9b 0x01>;
						phandle = <0x93>;
					};
				};

				q6adm {
					compatible = "qcom,q6adm";
					reg = <0x08>;
					phandle = <0xfe>;

					routing {
						compatible = "qcom,q6adm-routing";
						#sound-dai-cells = <0x00>;
						phandle = <0x95>;
					};
				};
			};
		};
	};

	adsp-smp2p {
		compatible = "qcom,smp2p";
		qcom,smem = <0x1bb 0x1ad>;
		interrupts = <0x00 0x9e 0x01>;
		mboxes = <0x14 0x0a>;
		qcom,local-pid = <0x00>;
		qcom,remote-pid = <0x02>;

		master-kernel {
			qcom,entry-name = "master-kernel";
			#qcom,smem-state-cells = <0x01>;
			phandle = <0x9a>;
		};

		slave-kernel {
			qcom,entry-name = "slave-kernel";
			interrupt-controller;
			#interrupt-cells = <0x02>;
			phandle = <0x98>;
		};
	};

	modem-smp2p {
		compatible = "qcom,smp2p";
		qcom,smem = <0x1b3 0x1ac>;
		interrupts = <0x00 0x1c3 0x01>;
		mboxes = <0x14 0x0e>;
		qcom,local-pid = <0x00>;
		qcom,remote-pid = <0x01>;

		master-kernel {
			qcom,entry-name = "master-kernel";
			#qcom,smem-state-cells = <0x01>;
			phandle = <0xff>;
		};

		slave-kernel {
			qcom,entry-name = "slave-kernel";
			interrupt-controller;
			#interrupt-cells = <0x02>;
			phandle = <0x100>;
		};
	};

	smp2p-slpi {
		compatible = "qcom,smp2p";
		qcom,smem = <0x1e1 0x1ae>;
		interrupts = <0x00 0xb2 0x01>;
		mboxes = <0x14 0x1a>;
		qcom,local-pid = <0x00>;
		qcom,remote-pid = <0x03>;

		slave-kernel {
			qcom,entry-name = "slave-kernel";
			interrupt-controller;
			#interrupt-cells = <0x02>;
			phandle = <0x101>;
		};

		master-kernel {
			qcom,entry-name = "master-kernel";
			#qcom,smem-state-cells = <0x01>;
			phandle = <0x102>;
		};
	};

	aliases {
		serial0 = "/soc/serial@75b0000";
		serial1 = "/soc/serial@75b1000";
		serial2 = "/soc/serial@7570000";
		i2c0 = "/soc/i2c@7577000";
		i2c1 = "/soc/i2c@75b6000";
		i2c2 = "/soc/i2c@75b5000";
		spi0 = "/soc/spi@7575000";
		spi1 = "/soc/spi@75ba000";
	};

	gpio_keys {
		compatible = "gpio-keys";
		#address-cells = <0x01>;
		#size-cells = <0x00>;
		autorepeat;
		pinctrl-names = "default";
		pinctrl-0 = <0x9c>;

		button@0 {
			label = "Volume Up";
			linux,code = <0x73>;
			gpios = <0x0e 0x02 0x01>;
		};
	};

	__symbols__ {
		mba_region = "/reserved-memory/mba@91500000";
		slpi_region = "/reserved-memory/slpi@90b00000";
		venus_region = "/reserved-memory/venus@90400000";
		adsp_region = "/reserved-memory/adsp@8ea00000";
		mpss_region = "/reserved-memory/mpss@88800000";
		smem_mem = "/reserved-memory/smem-mem@86000000";
		zap_shader_region = "/reserved-memory/gpu@8f200000";
		CPU0 = "/cpus/cpu@0";
		L2_0 = "/cpus/cpu@0/l2-cache";
		CPU1 = "/cpus/cpu@1";
		CPU2 = "/cpus/cpu@100";
		L2_1 = "/cpus/cpu@100/l2-cache";
		CPU3 = "/cpus/cpu@101";
		CPU_SLEEP_0 = "/cpus/idle-states/cpu-sleep-0";
		cpu0_alert0 = "/thermal-zones/cpu0-thermal/trips/trip-point@0";
		cpu0_crit = "/thermal-zones/cpu0-thermal/trips/cpu_crit";
		cpu1_alert0 = "/thermal-zones/cpu1-thermal/trips/trip-point@0";
		cpu1_crit = "/thermal-zones/cpu1-thermal/trips/cpu_crit";
		cpu2_alert0 = "/thermal-zones/cpu2-thermal/trips/trip-point@0";
		cpu2_crit = "/thermal-zones/cpu2-thermal/trips/cpu_crit";
		cpu3_alert0 = "/thermal-zones/cpu3-thermal/trips/trip-point@0";
		cpu3_crit = "/thermal-zones/cpu3-thermal/trips/cpu_crit";
		gpu1_alert0 = "/thermal-zones/gpu-thermal-top/trips/trip-point@0";
		gpu2_alert0 = "/thermal-zones/gpu-thermal-bottom/trips/trip-point@0";
		m4m_alert0 = "/thermal-zones/m4m-thermal/trips/trip-point@0";
		l3_or_venus_alert0 = "/thermal-zones/l3-or-venus-thermal/trips/trip-point@0";
		cluster0_l2_alert0 = "/thermal-zones/cluster0-l2-thermal/trips/trip-point@0";
		cluster1_l2_alert0 = "/thermal-zones/cluster1-l2-thermal/trips/trip-point@0";
		camera_alert0 = "/thermal-zones/camera-thermal/trips/trip-point@0";
		q6_dsp_alert0 = "/thermal-zones/q6-dsp-thermal/trips/trip-point@0";
		mem_alert0 = "/thermal-zones/mem-thermal/trips/trip-point@0";
		modemtx_alert0 = "/thermal-zones/modemtx-thermal/trips/trip-point@0";
		xo_board = "/clocks/xo_board";
		sleep_clk = "/clocks/sleep_clk";
		divclk4 = "/clocks/divclk4";
		div1_mclk = "/clocks/divclk1";
		tcsr_mutex = "/hwlock";
		rpmcc = "/rpm-glink/rpm_requests/qcom,rpmcc";
		rpmpd = "/rpm-glink/rpm_requests/power-controller";
		rpmpd_opp_table = "/rpm-glink/rpm_requests/power-controller/opp-table";
		rpmpd_opp1 = "/rpm-glink/rpm_requests/power-controller/opp-table/opp1";
		rpmpd_opp2 = "/rpm-glink/rpm_requests/power-controller/opp-table/opp2";
		rpmpd_opp3 = "/rpm-glink/rpm_requests/power-controller/opp-table/opp3";
		rpmpd_opp4 = "/rpm-glink/rpm_requests/power-controller/opp-table/opp4";
		rpmpd_opp5 = "/rpm-glink/rpm_requests/power-controller/opp-table/opp5";
		rpmpd_opp6 = "/rpm-glink/rpm_requests/power-controller/opp-table/opp6";
		pm8994_s1 = "/rpm-glink/rpm_requests/pm8994-regulators/s1";
		pm8994_s2 = "/rpm-glink/rpm_requests/pm8994-regulators/s2";
		pm8994_s3 = "/rpm-glink/rpm_requests/pm8994-regulators/s3";
		pm8994_s4 = "/rpm-glink/rpm_requests/pm8994-regulators/s4";
		pm8994_s5 = "/rpm-glink/rpm_requests/pm8994-regulators/s5";
		pm8994_s6 = "/rpm-glink/rpm_requests/pm8994-regulators/s6";
		pm8994_s7 = "/rpm-glink/rpm_requests/pm8994-regulators/s7";
		pm8994_s8 = "/rpm-glink/rpm_requests/pm8994-regulators/s8";
		pm8994_s9 = "/rpm-glink/rpm_requests/pm8994-regulators/s9";
		pm8994_s10 = "/rpm-glink/rpm_requests/pm8994-regulators/s10";
		pm8994_s11 = "/rpm-glink/rpm_requests/pm8994-regulators/s11";
		pm8994_s12 = "/rpm-glink/rpm_requests/pm8994-regulators/s12";
		pm8994_l1 = "/rpm-glink/rpm_requests/pm8994-regulators/l1";
		pm8994_l2 = "/rpm-glink/rpm_requests/pm8994-regulators/l2";
		pm8994_l3 = "/rpm-glink/rpm_requests/pm8994-regulators/l3";
		pm8994_l4 = "/rpm-glink/rpm_requests/pm8994-regulators/l4";
		pm8994_l5 = "/rpm-glink/rpm_requests/pm8994-regulators/l5";
		pm8994_l6 = "/rpm-glink/rpm_requests/pm8994-regulators/l6";
		pm8994_l7 = "/rpm-glink/rpm_requests/pm8994-regulators/l7";
		pm8994_l8 = "/rpm-glink/rpm_requests/pm8994-regulators/l8";
		pm8994_l9 = "/rpm-glink/rpm_requests/pm8994-regulators/l9";
		pm8994_l10 = "/rpm-glink/rpm_requests/pm8994-regulators/l10";
		pm8994_l11 = "/rpm-glink/rpm_requests/pm8994-regulators/l11";
		pm8994_l12 = "/rpm-glink/rpm_requests/pm8994-regulators/l12";
		pm8994_l13 = "/rpm-glink/rpm_requests/pm8994-regulators/l13";
		pm8994_l14 = "/rpm-glink/rpm_requests/pm8994-regulators/l14";
		pm8994_l15 = "/rpm-glink/rpm_requests/pm8994-regulators/l15";
		pm8994_l16 = "/rpm-glink/rpm_requests/pm8994-regulators/l16";
		pm8994_l17 = "/rpm-glink/rpm_requests/pm8994-regulators/l17";
		pm8994_l18 = "/rpm-glink/rpm_requests/pm8994-regulators/l18";
		pm8994_l19 = "/rpm-glink/rpm_requests/pm8994-regulators/l19";
		pm8994_l20 = "/rpm-glink/rpm_requests/pm8994-regulators/l20";
		pm8994_l21 = "/rpm-glink/rpm_requests/pm8994-regulators/l21";
		pm8994_l22 = "/rpm-glink/rpm_requests/pm8994-regulators/l22";
		pm8994_l23 = "/rpm-glink/rpm_requests/pm8994-regulators/l23";
		pm8994_l24 = "/rpm-glink/rpm_requests/pm8994-regulators/l24";
		pm8994_l25 = "/rpm-glink/rpm_requests/pm8994-regulators/l25";
		pm8994_l26 = "/rpm-glink/rpm_requests/pm8994-regulators/l26";
		pm8994_l27 = "/rpm-glink/rpm_requests/pm8994-regulators/l27";
		pm8994_l28 = "/rpm-glink/rpm_requests/pm8994-regulators/l28";
		pm8994_l29 = "/rpm-glink/rpm_requests/pm8994-regulators/l29";
		pm8994_l30 = "/rpm-glink/rpm_requests/pm8994-regulators/l30";
		pm8994_l31 = "/rpm-glink/rpm_requests/pm8994-regulators/l31";
		pm8994_l32 = "/rpm-glink/rpm_requests/pm8994-regulators/l32";
		soc = "/soc";
		rpm_msg_ram = "/soc/memory@68000";
		rng = "/soc/rng@83000";
		tcsr_mutex_regs = "/soc/syscon@740000";
		tsens0 = "/soc/thermal-sensor@4a9000";
		tsens1 = "/soc/thermal-sensor@4ad000";
		tcsr = "/soc/syscon@7a0000";
		intc = "/soc/interrupt-controller@9bc0000";
		apcs_glb = "/soc/mailbox@9820000";
		gcc = "/soc/clock-controller@300000";
		stm_out = "/soc/stm@3002000/out-ports/port/endpoint";
		tpiu_in = "/soc/tpiu@3020000/in-ports/port/endpoint";
		funnel0_in = "/soc/funnel@3021000/in-ports/port@7/endpoint";
		funnel0_out = "/soc/funnel@3021000/out-ports/port/endpoint";
		funnel1_in = "/soc/funnel@3022000/in-ports/port@6/endpoint";
		funnel1_out = "/soc/funnel@3022000/out-ports/port/endpoint";
		funnel2_out = "/soc/funnel@3023000/out-ports/port/endpoint";
		merge_funnel_in0 = "/soc/funnel@3025000/in-ports/port@0/endpoint";
		merge_funnel_in1 = "/soc/funnel@3025000/in-ports/port@1/endpoint";
		merge_funnel_in2 = "/soc/funnel@3025000/in-ports/port@2/endpoint";
		merge_funnel_out = "/soc/funnel@3025000/out-ports/port/endpoint";
		replicator_in = "/soc/replicator@3026000/in-ports/port/endpoint";
		replicator_out0 = "/soc/replicator@3026000/out-ports/port@0/endpoint";
		replicator_out1 = "/soc/replicator@3026000/out-ports/port@1/endpoint";
		etf_in = "/soc/etf@3027000/in-ports/port/endpoint";
		etf_out = "/soc/etf@3027000/out-ports/port/endpoint";
		etr_in = "/soc/etr@3028000/in-ports/port/endpoint";
		etm0_out = "/soc/etm@3840000/out-ports/port/endpoint";
		etm1_out = "/soc/etm@3940000/out-ports/port/endpoint";
		apss_funnel0_in0 = "/soc/funnel@39b0000/in-ports/port@0/endpoint";
		apss_funnel0_in1 = "/soc/funnel@39b0000/in-ports/port@1/endpoint";
		apss_funnel0_out = "/soc/funnel@39b0000/out-ports/port/endpoint";
		etm2_out = "/soc/etm@3a40000/out-ports/port/endpoint";
		etm3_out = "/soc/etm@3b40000/out-ports/port/endpoint";
		apss_funnel1_in0 = "/soc/funnel@3bb0000/in-ports/port@0/endpoint";
		apss_funnel1_in1 = "/soc/funnel@3bb0000/in-ports/port@1/endpoint";
		apss_funnel1_out = "/soc/funnel@3bb0000/out-ports/port/endpoint";
		apss_merge_funnel_in0 = "/soc/funnel@3bc0000/in-ports/port@0/endpoint";
		apss_merge_funnel_in1 = "/soc/funnel@3bc0000/in-ports/port@1/endpoint";
		apss_merge_funnel_out = "/soc/funnel@3bc0000/out-ports/port/endpoint";
		kryocc = "/soc/clock-controller@6400000";
		blsp1_uart1 = "/soc/serial@7570000";
		blsp1_spi0 = "/soc/spi@7575000";
		blsp2_i2c0 = "/soc/i2c@75b5000";
		blsp2_uart1 = "/soc/serial@75b0000";
		blsp2_i2c1 = "/soc/i2c@75b6000";
		blsp2_uart2 = "/soc/serial@75b1000";
		blsp1_i2c2 = "/soc/i2c@7577000";
		blsp2_spi5 = "/soc/spi@75ba000";
		sdhc2 = "/soc/sdhci@74a4900";
		msmgpio = "/soc/pinctrl@1010000";
		wcd_intr_default = "/soc/pinctrl@1010000/wcd9xxx_intr/wcd_intr_default";
		cdc_reset_sleep = "/soc/pinctrl@1010000/cdc_reset_ctrl/cdc_reset_sleep";
		cdc_reset_active = "/soc/pinctrl@1010000/cdc_reset_ctrl/cdc_reset_active";
		blsp1_spi0_default = "/soc/pinctrl@1010000/blsp1_spi0_default";
		blsp1_spi0_sleep = "/soc/pinctrl@1010000/blsp1_spi0_sleep";
		blsp1_i2c2_default = "/soc/pinctrl@1010000/blsp1_i2c2_default";
		blsp1_i2c2_sleep = "/soc/pinctrl@1010000/blsp1_i2c2_sleep";
		blsp2_i2c0_default = "/soc/pinctrl@1010000/blsp2_i2c0";
		blsp2_i2c0_sleep = "/soc/pinctrl@1010000/blsp2_i2c0_sleep";
		blsp2_uart1_2pins_default = "/soc/pinctrl@1010000/blsp2_uart1_2pins";
		blsp2_uart1_2pins_sleep = "/soc/pinctrl@1010000/blsp2_uart1_2pins_sleep";
		blsp2_uart1_4pins_default = "/soc/pinctrl@1010000/blsp2_uart1_4pins";
		blsp2_uart1_4pins_sleep = "/soc/pinctrl@1010000/blsp2_uart1_4pins_sleep";
		blsp2_i2c1_default = "/soc/pinctrl@1010000/blsp2_i2c1";
		blsp2_i2c1_sleep = "/soc/pinctrl@1010000/blsp2_i2c1_sleep";
		blsp2_uart2_2pins_default = "/soc/pinctrl@1010000/blsp2_uart2_2pins";
		blsp2_uart2_2pins_sleep = "/soc/pinctrl@1010000/blsp2_uart2_2pins_sleep";
		blsp2_uart2_4pins_default = "/soc/pinctrl@1010000/blsp2_uart2_4pins";
		blsp2_uart2_4pins_sleep = "/soc/pinctrl@1010000/blsp2_uart2_4pins_sleep";
		blsp2_spi5_default = "/soc/pinctrl@1010000/blsp2_spi5_default";
		blsp2_spi5_sleep = "/soc/pinctrl@1010000/blsp2_spi5_sleep";
		sdc2_clk_on = "/soc/pinctrl@1010000/sdc2_clk_on";
		sdc2_clk_off = "/soc/pinctrl@1010000/sdc2_clk_off";
		sdc2_cmd_on = "/soc/pinctrl@1010000/sdc2_cmd_on";
		sdc2_cmd_off = "/soc/pinctrl@1010000/sdc2_cmd_off";
		sdc2_data_on = "/soc/pinctrl@1010000/sdc2_data_on";
		sdc2_data_off = "/soc/pinctrl@1010000/sdc2_data_off";
		pcie0_clkreq_default = "/soc/pinctrl@1010000/pcie0_clkreq_default";
		pcie0_perst_default = "/soc/pinctrl@1010000/pcie0_perst_default";
		pcie0_wake_default = "/soc/pinctrl@1010000/pcie0_wake_default";
		pcie0_clkreq_sleep = "/soc/pinctrl@1010000/pcie0_clkreq_sleep";
		pcie0_wake_sleep = "/soc/pinctrl@1010000/pcie0_wake_sleep";
		pcie1_clkreq_default = "/soc/pinctrl@1010000/pcie1_clkreq_default";
		pcie1_perst_default = "/soc/pinctrl@1010000/pcie1_perst_default";
		pcie1_wake_default = "/soc/pinctrl@1010000/pcie1_wake_default";
		pcie1_clkreq_sleep = "/soc/pinctrl@1010000/pcie1_clkreq_sleep";
		pcie1_wake_sleep = "/soc/pinctrl@1010000/pcie1_wake_sleep";
		pcie2_clkreq_default = "/soc/pinctrl@1010000/pcie2_clkreq_default";
		pcie2_perst_default = "/soc/pinctrl@1010000/pcie2_perst_default";
		pcie2_wake_default = "/soc/pinctrl@1010000/pcie2_wake_default";
		pcie2_clkreq_sleep = "/soc/pinctrl@1010000/pcie2_clkreq_sleep";
		pcie2_wake_sleep = "/soc/pinctrl@1010000/pcie2_wake_sleep";
		cci0_default = "/soc/pinctrl@1010000/cci0_default";
		cci1_default = "/soc/pinctrl@1010000/cci1_default";
		camera_board_default = "/soc/pinctrl@1010000/camera_board_default";
		camera_front_default = "/soc/pinctrl@1010000/camera_front_default";
		camera_rear_default = "/soc/pinctrl@1010000/camera_rear_default";
		sdc2_cd_on = "/soc/pinctrl@1010000/sdc2_cd_on";
		sdc2_cd_off = "/soc/pinctrl@1010000/sdc2_cd_off";
		blsp1_uart1_default = "/soc/pinctrl@1010000/blsp1_uart1_default";
		blsp1_uart1_sleep = "/soc/pinctrl@1010000/blsp1_uart1_sleep";
		hdmi_hpd_active = "/soc/pinctrl@1010000/hdmi_hpd_active";
		hdmi_hpd_suspend = "/soc/pinctrl@1010000/hdmi_hpd_suspend";
		hdmi_ddc_active = "/soc/pinctrl@1010000/hdmi_ddc_active";
		hdmi_ddc_suspend = "/soc/pinctrl@1010000/hdmi_ddc_suspend";
		spmi_bus = "/soc/qcom,spmi@400f000";
		pm8994_gpios = "/soc/qcom,spmi@400f000/pmic@0/gpios@c000";
		ls_exp_gpio_f = "/soc/qcom,spmi@400f000/pmic@0/gpios@c000/pm8994_gpio5";
		bt_en_gpios = "/soc/qcom,spmi@400f000/pmic@0/gpios@c000/bt_en_gpios";
		wlan_en_gpios = "/soc/qcom,spmi@400f000/pmic@0/gpios@c000/wlan_en_gpios";
		audio_mclk = "/soc/qcom,spmi@400f000/pmic@0/gpios@c000/clk_div1";
		volume_up_gpio = "/soc/qcom,spmi@400f000/pmic@0/gpios@c000/pm8996_gpio2";
		divclk4_pin_a = "/soc/qcom,spmi@400f000/pmic@0/gpios@c000/divclk4";
		usb3_vbus_det_gpio = "/soc/qcom,spmi@400f000/pmic@0/gpios@c000/pm8996_gpio22";
		pm8994_mpps = "/soc/qcom,spmi@400f000/pmic@0/mpps@a000";
		pmi8994_gpios = "/soc/qcom,spmi@400f000/pmic@2/gpios@c000";
		usb2_vbus_det_gpio = "/soc/qcom,spmi@400f000/pmic@2/gpios@c000/pmi8996_gpio6";
		ufsphy = "/soc/phy@627000";
		ufshc = "/soc/ufshc@624000";
		mmcc = "/soc/clock-controller@8c0000";
		qusb2p_hstx_trim = "/soc/qfprom@74000/hstx_trim@24e";
		qusb2s_hstx_trim = "/soc/qfprom@74000/hstx_trim@24f";
		gpu_speed_bin = "/soc/qfprom@74000/gpu_speed_bin@133";
		pciephy_0 = "/soc/phy@34000/lane@35000";
		pciephy_1 = "/soc/phy@34000/lane@36000";
		pciephy_2 = "/soc/phy@34000/lane@37000";
		ssusb_phy_0 = "/soc/phy@7410000/lane@7410200";
		hsusb_phy1 = "/soc/phy@7411000";
		hsusb_phy2 = "/soc/phy@7412000";
		usb2 = "/soc/usb@76f8800";
		usb3 = "/soc/usb@6af8800";
		vfe_smmu = "/soc/iommu@da0000";
		camss = "/soc/camss@a00000";
		adreno_smmu = "/soc/iommu@b40000";
		mdp_smmu = "/soc/iommu@d00000";
		lpass_q6_smmu = "/soc/iommu@1600000";
		pcie0 = "/soc/agnoc@0/pcie@600000";
		pcie1 = "/soc/agnoc@0/pcie@608000";
		pcie2 = "/soc/agnoc@0/pcie@610000";
		slimbam = "/soc/dma@9184000";
		slim_msm = "/soc/slim@91c0000";
		tasha_ifd = "/soc/slim@91c0000/ngd@1/tas-ifd";
		wcd9335 = "/soc/slim@91c0000/ngd@1/codec@1";
		gpu_opp_table = "/soc/gpu@b00000/opp-table";
		mdss = "/soc/mdss@900000";
		mdp = "/soc/mdss@900000/mdp@901000";
		mdp5_intf3_out = "/soc/mdss@900000/mdp@901000/ports/port@0/endpoint";
		hdmi = "/soc/mdss@900000/hdmi-tx@9a0000";
		hdmi_in = "/soc/mdss@900000/hdmi-tx@9a0000/ports/port@0/endpoint";
		hdmi_phy = "/soc/mdss@900000/hdmi-phy@9a0600";
		venus_smmu = "/soc/arm,smmu-venus@d40000";
		usb3_id = "/soc/usb3-id";
		usb2_id = "/soc/usb2-id";
		wlan_en = "/soc/wlan-en-1-8v";
		sound = "/sound";
		q6afe = "/adsp-pil/smd-edge/apr/q6afe";
		q6afedai = "/adsp-pil/smd-edge/apr/q6afe/dais";
		q6asm = "/adsp-pil/smd-edge/apr/q6asm";
		q6asmdai = "/adsp-pil/smd-edge/apr/q6asm/dais";
		q6adm = "/adsp-pil/smd-edge/apr/q6adm";
		q6routing = "/adsp-pil/smd-edge/apr/q6adm/routing";
		adsp_smp2p_out = "/adsp-smp2p/master-kernel";
		adsp_smp2p_in = "/adsp-smp2p/slave-kernel";
		modem_smp2p_out = "/modem-smp2p/master-kernel";
		modem_smp2p_in = "/modem-smp2p/slave-kernel";
		slpi_smp2p_in = "/smp2p-slpi/slave-kernel";
		slpi_smp2p_out = "/smp2p-slpi/master-kernel";
	};
};
